VERSION "2021.24.4"

NS_ :

BS_:

BU_: VEH CH Receiver X

BA_DEF_ BO_ "GenMsgSendType" ENUM "Cyclic";
BA_DEF_ BO_ "GenMsgCycleTime" INT 0 10000;

BO_ 1274 USM_alertCleared: 8 Vector__XXX
 SG_ USM_alertClearedID : 0|8@1+ (1,0) [0|0] "" Vector__XXX

BO_ 1278 USM_logging10Hz: 8 Vector__XXX
 SG_ USM_rearSensorsHSDCurrent : 10|10@1+ (0.005865102639296188,0) [0|0] "" Vector__XXX
 SG_ USM_frontSensorsHSDCurrent : 0|10@1+ (0.005865102639296188,0) [0|0] "" Vector__XXX

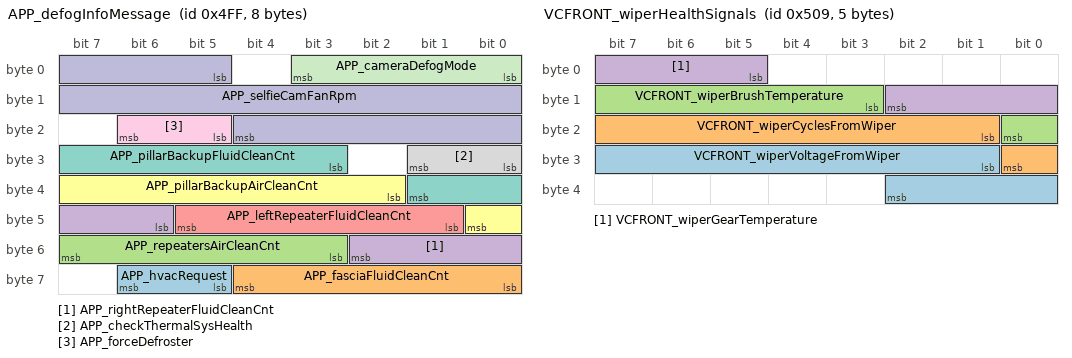
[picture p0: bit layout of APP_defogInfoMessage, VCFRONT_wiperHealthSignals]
BO_ 1279 APP_defogInfoMessage: 8 Vector__XXX
 SG_ APP_hvacRequest : 61|2@1+ (1,0) [0|0] "" Vector__XXX
 SG_ APP_fasciaFluidCleanCnt : 56|5@1+ (1,0) [0|0] "" Vector__XXX
 SG_ APP_repeatersAirCleanCnt : 51|5@1+ (1,0) [0|0] "" Vector__XXX
 SG_ APP_rightRepeaterFluidCleanCnt : 46|5@1+ (1,0) [0|0] "" Vector__XXX
 SG_ APP_leftRepeaterFluidCleanCnt : 41|5@1+ (1,0) [0|0] "" Vector__XXX
 SG_ APP_pillarBackupAirCleanCnt : 34|7@1+ (1,0) [0|0] "" Vector__XXX
 SG_ APP_pillarBackupFluidCleanCnt : 27|7@1+ (1,0) [0|0] "" Vector__XXX
 SG_ APP_checkThermalSysHealth : 24|2@1+ (1,0) [0|0] "" Vector__XXX
 SG_ APP_forceDefroster : 21|2@1+ (1,0) [0|0] "" Vector__XXX
 SG_ APP_selfieCamFanRpm : 5|16@1+ (1,0) [0|0] "" Vector__XXX
 SG_ APP_cameraDefogMode : 0|4@1+ (1,0) [0|0] "" Vector__XXX

BO_ 1281 VCFRONT_bootID: 12 Vector__XXX
 SG_ VCFRONT_bootFirmwareType : 63|8@0+ (1,0) [0|0] "" Vector__XXX
 SG_ VCFRONT_bootUsageId : 39|16@0+ (1,0) [0|0] "" Vector__XXX
 SG_ VCFRONT_bootAssemblyId : 31|8@0+ (1,0) [0|0] "" Vector__XXX
 SG_ VCFRONT_bootPcbaId : 23|8@0+ (1,0) [0|0] "" Vector__XXX
 SG_ VCFRONT_bootComponentId : 7|16@0+ (1,0) [0|0] "" Vector__XXX

BO_ 1283 VCRIGHT_bootID: 12 Vector__XXX
 SG_ VCRIGHT_bootFirmwareType : 63|8@0+ (1,0) [0|0] "" Vector__XXX
 SG_ VCRIGHT_bootUsageId : 39|16@0+ (1,0) [0|0] "" Vector__XXX
 SG_ VCRIGHT_bootAssemblyId : 31|8@0+ (1,0) [0|0] "" Vector__XXX
 SG_ VCRIGHT_bootPcbaId : 23|8@0+ (1,0) [0|0] "" Vector__XXX
 SG_ VCRIGHT_bootComponentId : 7|16@0+ (1,0) [0|0] "" Vector__XXX

BO_ 1284 PCS_bootID: 12 Vector__XXX
 SG_ PCS_bootFirmwareType : 63|8@0+ (1,0) [0|0] "" Vector__XXX
 SG_ PCS_bootUsageId : 39|16@0+ (1,0) [0|0] "" Vector__XXX
 SG_ PCS_bootAssemblyId : 31|8@0+ (1,0) [0|0] "" Vector__XXX
 SG_ PCS_bootPcbaId : 23|8@0+ (1,0) [0|0] "" Vector__XXX
 SG_ PCS_bootComponentId : 7|16@0+ (1,0) [0|0] "" Vector__XXX

BO_ 1285 ESP_alertLog: 8 Vector__XXX
 SG_ ESP_alertState : 15|1@1+ (1,0) [0|0] "" Vector__XXX
 SG_ ESP_alertID : 0|9@1+ (1,0) [0|0] "" Vector__XXX

BO_ 1289 VCFRONT_wiperHealthSignals: 5 Vector__XXX
 SG_ VCFRONT_wiperVoltageFromWiper : 25|10@1+ (0.01,8) [0|0] "" Vector__XXX
 SG_ VCFRONT_wiperCyclesFromWiper : 17|8@1+ (6000,0) [0|0] "" Vector__XXX
 SG_ VCFRONT_wiperBrushTemperature : 11|6@1+ (1.6,100) [0|0] "" Vector__XXX
 SG_ VCFRONT_wiperGearTemperature : 5|6@1+ (1,40) [0|0] "" Vector__XXX

BO_ 1290 HVP_alertLog: 8 Vector__XXX
 SG_ HVP_a040_negCtrAuxOpen m40 : 63|1@1+ (1,0) [0|0] "" Vector__XXX
 SG_ HVP_a040_posCtrAuxOpen m40 : 62|1@1+ (1,0) [0|0] "" Vector__XXX
 SG_ HVP_a026_difVoltage m26 : 56|8@1+ (0.04,0) [0|0] "" Vector__XXX
 SG_ HVP_a033_pwmDutyCyleNegative m33 : 56|8@1+ (1,0) [0|0] "" Vector__XXX
 SG_ HVP_a035_pwmDutyCyleNegative m35 : 56|8@1+ (1,0) [0|0] "" Vector__XXX
 SG_ HVP_a063_numFailedBricks m63 : 56|8@1+ (1,0) [0|0] "" Vector__XXX
 SG_ HVP_a064_numFailedAux m64 : 56|8@1+ (1,0) [0|0] "" Vector__XXX
 SG_ HVP_a018_gpioChgEnable m18 : 52|1@1+ (1,0) [0|0] "" Vector__XXX
 SG_ HVP_a018_gpioDcDcEnable m18 : 51|1@1+ (1,0) [0|0] "" Vector__XXX
 SG_ HVP_a049_negCtrState m49 : 51|3@1+ (1,0) [0|0] "" Vector__XXX
 SG_ HVP_a050_negCtrState m50 : 51|3@1+ (1,0) [0|0] "" Vector__XXX
 SG_ HVP_a056_negFcContactorState m56 : 51|3@1+ (1,0) [0|0] "" Vector__XXX
 SG_ HVP_a018_gpioLogicPowerEnable m18 : 50|1@1+ (1,0) [0|0] "" Vector__XXX
 SG_ HVP_a018_pcsHardwareOkToBePowerC m18 : 49|1@1+ (1,0) [0|0] "" Vector__XXX
 SG_ HVP_a000_alertDataW2 m0 : 48|16@1+ (1,0) [0|0] "" Vector__XXX
 SG_ HVP_a018_hvcHardwareSupportsCycl m18 : 48|1@1+ (1,0) [0|0] "" Vector__XXX
 SG_ HVP_a020_shuntTemperature m20 : 48|16@1- (0.01,0) [0|0] "" Vector__XXX
 SG_ HVP_a025_packVoltage m25 : 48|16@1+ (0.1,0) [0|0] "" Vector__XXX
 SG_ HVP_a026_dirVoltage m26 : 48|8@1+ (0.04,0) [0|0] "" Vector__XXX
 SG_ HVP_a033_pwmDutyCylePositive m33 : 48|8@1+ (1,0) [0|0] "" Vector__XXX
 SG_ HVP_a035_pwmDutyCylePositive m35 : 48|8@1+ (1,0) [0|0] "" Vector__XXX
 SG_ HVP_a046_asicTemperature m46 : 48|16@1- (0.01,0) [0|0] "" Vector__XXX
 SG_ HVP_a049_posCtrState m49 : 48|3@1+ (1,0) [0|0] "" Vector__XXX
 SG_ HVP_a050_posCtrState m50 : 48|3@1+ (1,0) [0|0] "" Vector__XXX
 SG_ HVP_a051_energyReserveV m51 : 48|16@1+ (0.001,0) [0|0] "" Vector__XXX
 SG_ HVP_a056_posFcContactorState m56 : 48|3@1+ (1,0) [0|0] "" Vector__XXX
 SG_ HVP_a060_stackId m60 : 48|8@1+ (1,1) [0|0] "" Vector__XXX
 SG_ HVP_a063_brickId m63 : 48|8@1+ (1,1) [0|0] "" Vector__XXX
 SG_ HVP_a064_auxId m64 : 48|8@1+ (1,1) [0|0] "" Vector__XXX
 SG_ HVP_a068_energyReserveV m68 : 48|16@1+ (0.001,0) [0|0] "" Vector__XXX
 SG_ HVP_a040_negCtrVoltageDrop m40 : 47|15@1- (0.1,0) [0|0] "" Vector__XXX
 SG_ HVP_a018_remainingPcsRecoveriesA m18 : 46|2@1+ (1,0) [0|0] "" Vector__XXX
 SG_ HVP_a018_remainingPcsPowerCycles m18 : 44|2@1+ (1,0) [0|0] "" Vector__XXX
 SG_ HVP_a021_Aout m21 : 44|14@1+ (0.001,0) [0|0] "" Vector__XXX
 SG_ HVP_a021_LowSide m21 : 43|1@1+ (1,0) [0|0] "" Vector__XXX
 SG_ HVP_a056_negPackContactorState m56 : 43|3@1+ (1,0) [0|0] "" Vector__XXX
 SG_ HVP_a021_HighSide m21 : 42|1@1+ (1,0) [0|0] "" Vector__XXX
 SG_ HVP_a021_OneShotSequence m21 : 41|1@1+ (1,0) [0|0] "" Vector__XXX
 SG_ HVP_a022_SquibResistance m22 : 40|16@1+ (0.001,0) [0|0] "" Vector__XXX
 SG_ HVP_a026_internalVoltage m26 : 40|8@1+ (0.04,0) [0|0] "" Vector__XXX
 SG_ HVP_a036_pyroFiringAttempt m36 : 40|4@1+ (1,0) [0|0] "" Vector__XXX
 SG_ HVP_a056_posPackContactorState m56 : 40|3@1+ (1,0) [0|0] "" Vector__XXX
 SG_ HVP_a009_primaryChainSensor m9 : 39|1@1+ (1,0) [0|0] "" Vector__XXX
 SG_ HVP_a010_primaryChainSensor m10 : 39|1@1+ (1,0) [0|0] "" Vector__XXX
 SG_ HVP_a008_primaryChainSensor m8 : 38|1@1+ (1,0) [0|0] "" Vector__XXX
 SG_ HVP_a058_VrefType m58 : 38|2@1+ (1,0) [0|0] "" Vector__XXX
 SG_ HVP_a059_VrefType m59 : 38|2@1+ (1,0) [0|0] "" Vector__XXX
 SG_ HVP_a042_cpVersionMismatch m42 : 37|1@1+ (1,0) [0|0] "" Vector__XXX
 SG_ HVP_a041_dcLinkOverVoltage m41 : 36|1@1+ (1,0) [0|0] "" Vector__XXX
 SG_ HVP_a042_resetRequestRequired m42 : 36|1@1+ (1,0) [0|0] "" Vector__XXX
 SG_ HVP_a057_readSTAT m57 : 36|1@1+ (1,0) [0|0] "" Vector__XXX
 SG_ HVP_a058_VrefStatus m58 : 36|2@1+ (1,0) [0|0] "" Vector__XXX
 SG_ HVP_a059_VrefStatus m59 : 36|2@1+ (1,0) [0|0] "" Vector__XXX
 SG_ HVP_a041_pyroFault m41 : 35|1@1+ (1,0) [0|0] "" Vector__XXX
 SG_ HVP_a042_packContactorOpening m42 : 35|1@1+ (1,0) [0|0] "" Vector__XXX
 SG_ HVP_a057_readAUXB m57 : 35|1@1+ (1,0) [0|0] "" Vector__XXX
 SG_ HVP_a041_resetRequestRequired m41 : 34|1@1+ (1,0) [0|0] "" Vector__XXX
 SG_ HVP_a042_packContactorClosing m42 : 34|1@1+ (1,0) [0|0] "" Vector__XXX
 SG_ HVP_a057_readAUXA m57 : 34|1@1+ (1,0) [0|0] "" Vector__XXX
 SG_ HVP_a041_fcContactorOpening m41 : 33|1@1+ (1,0) [0|0] "" Vector__XXX
 SG_ HVP_a042_shuntCurrentMia m42 : 33|1@1+ (1,0) [0|0] "" Vector__XXX
 SG_ HVP_a057_readSNF m57 : 33|1@1+ (1,0) [0|0] "" Vector__XXX
 SG_ HVP_a000_alertDataW1 m0 : 32|16@1+ (1,0) [0|0] "" Vector__XXX
 SG_ HVP_a008_sensorId m8 : 32|6@1+ (1,1) [0|0] "" Vector__XXX
 SG_ HVP_a009_brickId m9 : 32|7@1+ (1,1) [0|0] "" Vector__XXX
 SG_ HVP_a010_brickId m10 : 32|7@1+ (1,1) [0|0] "" Vector__XXX
 SG_ HVP_a013_bmbChainBreakType m13 : 32|3@1+ (1,0) [0|0] "" Vector__XXX
 SG_ HVP_a018_battery12V m18 : 32|12@1+ (0.1,0) [0|0] "" Vector__XXX
 SG_ HVP_a020_shuntCurrentAux m20 : 32|16@1- (0.1,0) [0|0] "" Vector__XXX
 SG_ HVP_a023_reason m23 : 32|2@1+ (1,0) [0|0] "" Vector__XXX
 SG_ HVP_a025_voltage2 m25 : 32|16@1+ (0.1,0) [0|0] "" Vector__XXX
 SG_ HVP_a026_outputVoltage m26 : 32|8@1+ (0.04,0) [0|0] "" Vector__XXX
 SG_ HVP_a028_sumOfBrickV m28 : 32|16@1+ (0.1,0) [0|0] "" Vector__XXX
 SG_ HVP_a030_dcPositiveLinkV m30 : 32|16@1- (0.1,0) [0|0] "" Vector__XXX
 SG_ HVP_a031_dcNegativeLinkV m31 : 32|16@1- (0.1,0) [0|0] "" Vector__XXX
 SG_ HVP_a033_coilCurrent m33 : 32|16@1+ (0.1,0) [0|0] "" Vector__XXX
 SG_ HVP_a035_coilCurrent m35 : 32|16@1+ (0.1,0) [0|0] "" Vector__XXX
 SG_ HVP_a040_posCtrVoltageDrop m40 : 32|15@1- (0.1,0) [0|0] "" Vector__XXX
 SG_ HVP_a041_fcContactorClosing m41 : 32|1@1+ (1,0) [0|0] "" Vector__XXX
 SG_ HVP_a042_shuntHwMia m42 : 32|1@1+ (1,0) [0|0] "" Vector__XXX
 SG_ HVP_a046_shuntTemperature m46 : 32|16@1- (0.01,0) [0|0] "" Vector__XXX
 SG_ HVP_a047_auxCurrent m47 : 32|16@1- (0.1,0) [0|0] "" Vector__XXX
 SG_ HVP_a049_coilCurrent m49 : 32|16@1+ (0.1,0) [0|0] "" Vector__XXX
 SG_ HVP_a050_coilCurrent m50 : 32|16@1+ (0.1,0) [0|0] "" Vector__XXX
 SG_ HVP_a051_shuntCurrent m51 : 32|16@1- (0.1,0) [0|0] "" Vector__XXX
 SG_ HVP_a052_regErrorType m52 : 32|8@1+ (1,0) [0|0] "" Vector__XXX
 SG_ HVP_a053_dcLinkVoltage m53 : 32|16@1+ (0.01,0) [0|0] "" Vector__XXX
 SG_ HVP_a057_readSNE m57 : 32|1@1+ (1,0) [0|0] "" Vector__XXX
 SG_ HVP_a058_bmbDeviceId m58 : 32|4@1+ (1,1) [0|0] "" Vector__XXX
 SG_ HVP_a059_bmbDeviceId m59 : 32|4@1+ (1,1) [0|0] "" Vector__XXX
 SG_ HVP_a060_sumBrickVoltage m60 : 32|16@1+ (0.00128,0) [0|0] "" Vector__XXX
 SG_ HVP_a061_auxCurrent m61 : 32|16@1- (0.1,0) [0|0] "" Vector__XXX
 SG_ HVP_a063_secondaryBrickVoltage m63 : 32|16@1+ (0.0001,0) [0|0] "" Vector__XXX
 SG_ HVP_a064_secondaryAuxVoltage m64 : 32|16@1+ (0.0001,0) [0|0] "" Vector__XXX
 SG_ HVP_a068_shuntCurrent m68 : 32|16@1- (0.1,0) [0|0] "" Vector__XXX
 SG_ HVP_a041_gpoRequestActive m41 : 31|1@1+ (1,0) [0|0] "" Vector__XXX
 SG_ HVP_a042_contactorStateWelded m42 : 31|1@1+ (1,0) [0|0] "" Vector__XXX
 SG_ HVP_a044_cpVersionMismatch m44 : 31|1@1+ (1,0) [0|0] "" Vector__XXX
 SG_ HVP_a057_readSND m57 : 31|1@1+ (1,0) [0|0] "" Vector__XXX
 SG_ HVP_a041_packVoltageMismatch m41 : 30|1@1+ (1,0) [0|0] "" Vector__XXX
 SG_ HVP_a042_hvilFault m42 : 30|1@1+ (1,0) [0|0] "" Vector__XXX
 SG_ HVP_a044_contactorOpened m44 : 30|1@1+ (1,0) [0|0] "" Vector__XXX
 SG_ HVP_a057_readSNC m57 : 30|1@1+ (1,0) [0|0] "" Vector__XXX
 SG_ HVP_a012_bmbCommStatusTypeB m12 : 29|2@1+ (1,0) [0|0] "" Vector__XXX
 SG_ HVP_a013_bmbCommStatusTypeB m13 : 29|2@1+ (1,0) [0|0] "" Vector__XXX
 SG_ HVP_a041_shuntCurrentMia m41 : 29|1@1+ (1,0) [0|0] "" Vector__XXX
 SG_ HVP_a042_packVoltageMismatch m42 : 29|1@1+ (1,0) [0|0] "" Vector__XXX
 SG_ HVP_a044_packVoltageMismatch m44 : 29|1@1+ (1,0) [0|0] "" Vector__XXX
 SG_ HVP_a057_readSNB m57 : 29|1@1+ (1,0) [0|0] "" Vector__XXX
 SG_ HVP_a041_shuntHwMia m41 : 28|1@1+ (1,0) [0|0] "" Vector__XXX
 SG_ HVP_a042_supplyVer m42 : 28|1@1+ (1,0) [0|0] "" Vector__XXX
 SG_ HVP_a044_supplyVer m44 : 28|1@1+ (1,0) [0|0] "" Vector__XXX
 SG_ HVP_a057_readSNA m57 : 28|1@1+ (1,0) [0|0] "" Vector__XXX
 SG_ HVP_a041_contactorStateWelded m41 : 27|1@1+ (1,0) [0|0] "" Vector__XXX
 SG_ HVP_a042_supply12V m42 : 27|1@1+ (1,0) [0|0] "" Vector__XXX
 SG_ HVP_a044_supply12V m44 : 27|1@1+ (1,0) [0|0] "" Vector__XXX
 SG_ HVP_a057_readCVF m57 : 27|1@1+ (1,0) [0|0] "" Vector__XXX
 SG_ HVP_a041_hvilFault m41 : 26|1@1+ (1,0) [0|0] "" Vector__XXX
 SG_ HVP_a042_cpFault m42 : 26|1@1+ (1,0) [0|0] "" Vector__XXX
 SG_ HVP_a043_contactorOpened m43 : 26|1@1+ (1,0) [0|0] "" Vector__XXX
 SG_ HVP_a044_cpFault m44 : 26|1@1+ (1,0) [0|0] "" Vector__XXX
 SG_ HVP_a057_readCVE m57 : 26|1@1+ (1,0) [0|0] "" Vector__XXX
 SG_ HVP_a021_SquibResistance m21 : 25|16@1+ (0.001,0) [0|0] "" Vector__XXX
 SG_ HVP_a041_bmbMia m41 : 25|1@1+ (1,0) [0|0] "" Vector__XXX
 SG_ HVP_a042_cpMia m42 : 25|1@1+ (1,0) [0|0] "" Vector__XXX
 SG_ HVP_a043_bmbMia m43 : 25|1@1+ (1,0) [0|0] "" Vector__XXX
 SG_ HVP_a044_cpMia m44 : 25|1@1+ (1,0) [0|0] "" Vector__XXX
 SG_ HVP_a057_readCVD m57 : 25|1@1+ (1,0) [0|0] "" Vector__XXX
 SG_ HVP_a012_breakLocationB m12 : 24|5@1+ (1,0) [0|0] "" Vector__XXX
 SG_ HVP_a013_breakLocationB m13 : 24|5@1+ (1,0) [0|0] "" Vector__XXX
 SG_ HVP_a021_VstTestFailed m21 : 24|1@1+ (1,0) [0|0] "" Vector__XXX
 SG_ HVP_a022_Aout m22 : 24|14@1+ (0.001,0) [0|0] "" Vector__XXX
 SG_ HVP_a026_inputVoltage m26 : 24|8@1+ (0.04,0) [0|0] "" Vector__XXX
 SG_ HVP_a036_pyroFiringTime m36 : 24|16@1+ (1,0) [0|0] "" Vector__XXX
 SG_ HVP_a040_coilCurrent m40 : 24|8@1+ (0.1,0) [0|0] "" Vector__XXX
 SG_ HVP_a041_notAllowedtoEnergize m41 : 24|1@1+ (1,0) [0|0] "" Vector__XXX
 SG_ HVP_a042_bmsHvsMia m42 : 24|1@1+ (1,0) [0|0] "" Vector__XXX
 SG_ HVP_a043_notAllowedtoEnergize m43 : 24|1@1+ (1,0) [0|0] "" Vector__XXX
 SG_ HVP_a044_bmsHvsMia m44 : 24|1@1+ (1,0) [0|0] "" Vector__XXX
 SG_ HVP_a056_shuntCurrent m56 : 24|16@1- (0.1,0) [0|0] "" Vector__XXX
 SG_ HVP_a057_readCVC m57 : 24|1@1+ (1,0) [0|0] "" Vector__XXX
 SG_ HVP_a021_SquibResTestFailed m21 : 23|1@1+ (1,0) [0|0] "" Vector__XXX
 SG_ HVP_a041_packContactorHw m41 : 23|1@1+ (1,0) [0|0] "" Vector__XXX
 SG_ HVP_a042_notAllowedtoEnergize m42 : 23|1@1+ (1,0) [0|0] "" Vector__XXX
 SG_ HVP_a043_packContactorHw m43 : 23|1@1+ (1,0) [0|0] "" Vector__XXX
 SG_ HVP_a044_notAllowedtoEnergize m44 : 23|1@1+ (1,0) [0|0] "" Vector__XXX
 SG_ HVP_a057_readCVB m57 : 23|1@1+ (1,0) [0|0] "" Vector__XXX
 SG_ HVP_a021_PyroLeakTestFailed m21 : 22|1@1+ (1,0) [0|0] "" Vector__XXX
 SG_ HVP_a041_crashEvent m41 : 22|1@1+ (1,0) [0|0] "" Vector__XXX
 SG_ HVP_a042_fcContactorHw m42 : 22|1@1+ (1,0) [0|0] "" Vector__XXX
 SG_ HVP_a043_crashEvent m43 : 22|1@1+ (1,0) [0|0] "" Vector__XXX
 SG_ HVP_a044_fcContactorHw m44 : 22|1@1+ (1,0) [0|0] "" Vector__XXX
 SG_ HVP_a057_readCVA m57 : 22|1@1+ (1,0) [0|0] "" Vector__XXX
 SG_ HVP_a012_bmbCommStatusTypeA m12 : 21|2@1+ (1,0) [0|0] "" Vector__XXX
 SG_ HVP_a013_bmbCommStatusTypeA m13 : 21|2@1+ (1,0) [0|0] "" Vector__XXX
 SG_ HVP_a021_RefCurrentTestFailed m21 : 21|1@1+ (1,0) [0|0] "" Vector__XXX
 SG_ HVP_a022_LowSide m22 : 21|1@1+ (1,0) [0|0] "" Vector__XXX
 SG_ HVP_a041_underVoltage m41 : 21|1@1+ (1,0) [0|0] "" Vector__XXX
 SG_ HVP_a042_crashEvent m42 : 21|1@1+ (1,0) [0|0] "" Vector__XXX
 SG_ HVP_a043_underVoltage m43 : 21|1@1+ (1,0) [0|0] "" Vector__XXX
 SG_ HVP_a044_crashEvent m44 : 21|1@1+ (1,0) [0|0] "" Vector__XXX
 SG_ HVP_a065_brickId m65 : 21|7@1+ (1,1) [0|0] "" Vector__XXX
 SG_ HVP_a021_LowSideSwitchTestFailed m21 : 20|1@1+ (1,0) [0|0] "" Vector__XXX
 SG_ HVP_a022_HighSide m22 : 20|1@1+ (1,0) [0|0] "" Vector__XXX
 SG_ HVP_a041_overTemperature m41 : 20|1@1+ (1,0) [0|0] "" Vector__XXX
 SG_ HVP_a042_overTemperature m42 : 20|1@1+ (1,0) [0|0] "" Vector__XXX
 SG_ HVP_a043_overTemperature m43 : 20|1@1+ (1,0) [0|0] "" Vector__XXX
 SG_ HVP_a044_overTemperature m44 : 20|1@1+ (1,0) [0|0] "" Vector__XXX
 SG_ HVP_a067_hvilTypeIsFromCal m67 : 20|1@1+ (1,0) [0|0] "" Vector__XXX
 SG_ HVP_a021_HighSideSwitchTestFaile m21 : 19|1@1+ (1,0) [0|0] "" Vector__XXX
 SG_ HVP_a022_OneShotSequence m22 : 19|1@1+ (1,0) [0|0] "" Vector__XXX
 SG_ HVP_a041_overVoltage m41 : 19|1@1+ (1,0) [0|0] "" Vector__XXX
 SG_ HVP_a042_overVoltage m42 : 19|1@1+ (1,0) [0|0] "" Vector__XXX
 SG_ HVP_a043_overVoltage m43 : 19|1@1+ (1,0) [0|0] "" Vector__XXX
 SG_ HVP_a044_overVoltage m44 : 19|1@1+ (1,0) [0|0] "" Vector__XXX
 SG_ HVP_a021_ErTestFailed m21 : 18|1@1+ (1,0) [0|0] "" Vector__XXX
 SG_ HVP_a022_PyroLeakTestFailed m22 : 18|1@1+ (1,0) [0|0] "" Vector__XXX
 SG_ HVP_a041_overDischargeCurrent m41 : 18|1@1+ (1,0) [0|0] "" Vector__XXX
 SG_ HVP_a042_overDischargeCurrent m42 : 18|1@1+ (1,0) [0|0] "" Vector__XXX
 SG_ HVP_a043_overDischargeCurrent m43 : 18|1@1+ (1,0) [0|0] "" Vector__XXX
 SG_ HVP_a044_overDischargeCurrent m44 : 18|1@1+ (1,0) [0|0] "" Vector__XXX
 SG_ HVP_a057_bmbDeviceId m57 : 18|4@1+ (1,1) [0|0] "" Vector__XXX
 SG_ HVP_a067_hvilTypeFromGateway m67 : 18|2@1+ (1,0) [0|0] "" Vector__XXX
 SG_ HVP_a039_negContactorFailed m39 : 17|1@1+ (1,0) [0|0] "" Vector__XXX
 SG_ HVP_a041_overChargeCurrent m41 : 17|1@1+ (1,0) [0|0] "" Vector__XXX
 SG_ HVP_a042_overChargeCurrent m42 : 17|1@1+ (1,0) [0|0] "" Vector__XXX
 SG_ HVP_a043_overChargeCurrent m43 : 17|1@1+ (1,0) [0|0] "" Vector__XXX
 SG_ HVP_a044_overChargeCurrent m44 : 17|1@1+ (1,0) [0|0] "" Vector__XXX
 SG_ HVP_a000_alertDataW0 m0 : 16|16@1+ (1,0) [0|0] "" Vector__XXX
 SG_ HVP_a003_programCounter m3 : 16|32@1+ (1,0) [0|0] "" Vector__XXX
 SG_ HVP_a005_current m5 : 16|24@1- (0.001,0) [0|0] "" Vector__XXX
 SG_ HVP_a006_current m6 : 16|24@1- (0.001,0) [0|0] "" Vector__XXX
 SG_ HVP_a007_current m7 : 16|24@1- (0.001,0) [0|0] "" Vector__XXX
 SG_ HVP_a008_temperature m8 : 16|16@1- (0.01,0) [0|0] "" Vector__XXX
 SG_ HVP_a009_brickVoltage m9 : 16|16@1- (0.001,0) [0|0] "" Vector__XXX
 SG_ HVP_a010_brickVoltage m10 : 16|16@1- (0.001,0) [0|0] "" Vector__XXX
 SG_ HVP_a012_breakLocationA m12 : 16|5@1+ (1,0) [0|0] "" Vector__XXX
 SG_ HVP_a013_breakLocationA m13 : 16|5@1+ (1,0) [0|0] "" Vector__XXX
 SG_ HVP_a018_dcLinkVoltage m18 : 16|16@1+ (0.01,0) [0|0] "" Vector__XXX
 SG_ HVP_a020_energyReserveV m20 : 16|16@1+ (0.001,0) [0|0] "" Vector__XXX
 SG_ HVP_a021_pyroStatus m21 : 16|2@1+ (1,0) [0|0] "" Vector__XXX
 SG_ HVP_a022_pyroStatus m22 : 16|2@1+ (1,0) [0|0] "" Vector__XXX
 SG_ HVP_a023_bmbDeviceMask m23 : 16|16@1+ (1,0) [0|0] "" Vector__XXX
 SG_ HVP_a024_voltage m24 : 16|16@1+ (0.1,0) [0|0] "" Vector__XXX
 SG_ HVP_a025_voltage1 m25 : 16|16@1+ (0.1,0) [0|0] "" Vector__XXX
 SG_ HVP_a026_hvilStatus m26 : 16|4@1+ (1,0) [0|0] "" Vector__XXX
 SG_ HVP_a028_packVoltage m28 : 16|16@1+ (0.1,0) [0|0] "" Vector__XXX
 SG_ HVP_a030_packPositiveLinkV m30 : 16|16@1- (0.1,0) [0|0] "" Vector__XXX
 SG_ HVP_a031_packNegativeLinkV m31 : 16|16@1- (0.1,0) [0|0] "" Vector__XXX
 SG_ HVP_a033_contactorPowerV m33 : 16|16@1+ (0.1,0) [0|0] "" Vector__XXX
 SG_ HVP_a035_contactorPowerV m35 : 16|16@1+ (0.1,0) [0|0] "" Vector__XXX
 SG_ HVP_a036_pyroFiringHandle m36 : 16|4@1+ (1,0) [0|0] "" Vector__XXX
 SG_ HVP_a037_pyroFiringHandle m37 : 16|4@1+ (1,0) [0|0] "" Vector__XXX
 SG_ HVP_a039_posContactorFailed m39 : 16|1@1+ (1,0) [0|0] "" Vector__XXX
 SG_ HVP_a040_powerVoltage m40 : 16|8@1+ (0.1,0) [0|0] "" Vector__XXX
 SG_ HVP_a041_overCurrent m41 : 16|1@1+ (1,0) [0|0] "" Vector__XXX
 SG_ HVP_a042_overCurrent m42 : 16|1@1+ (1,0) [0|0] "" Vector__XXX
 SG_ HVP_a043_overCurrent m43 : 16|1@1+ (1,0) [0|0] "" Vector__XXX
 SG_ HVP_a044_overCurrent m44 : 16|1@1+ (1,0) [0|0] "" Vector__XXX
 SG_ HVP_a045_dcLinkVoltage m45 : 16|16@1+ (0.1,0) [0|0] "" Vector__XXX
 SG_ HVP_a046_shuntCurrent m46 : 16|16@1- (0.1,0) [0|0] "" Vector__XXX
 SG_ HVP_a047_shuntCurrent m47 : 16|16@1- (0.1,0) [0|0] "" Vector__XXX
 SG_ HVP_a049_contactorPowerV m49 : 16|16@1+ (0.1,0) [0|0] "" Vector__XXX
 SG_ HVP_a050_contactorPowerV m50 : 16|16@1+ (0.1,0) [0|0] "" Vector__XXX
 SG_ HVP_a051_shuntTemperature m51 : 16|16@1- (0.01,0) [0|0] "" Vector__XXX
 SG_ HVP_a052_bmbDeviceMask m52 : 16|16@1+ (1,0) [0|0] "" Vector__XXX
 SG_ HVP_a053_packVoltage m53 : 16|16@1+ (0.01,0) [0|0] "" Vector__XXX
 SG_ HVP_a056_diagnosis m56 : 16|2@1+ (1,0) [0|0] "" Vector__XXX
 SG_ HVP_a057_bmbDiagnosticsType m57 : 16|2@1+ (1,0) [0|0] "" Vector__XXX
 SG_ HVP_a058_VrefSample m58 : 16|16@1+ (0.0001,0) [0|0] "" Vector__XXX
 SG_ HVP_a059_VrefSample m59 : 16|16@1+ (0.0001,0) [0|0] "" Vector__XXX
 SG_ HVP_a060_stackVoltage m60 : 16|16@1+ (0.00128,0) [0|0] "" Vector__XXX
 SG_ HVP_a061_shuntCurrent m61 : 16|16@1- (0.1,0) [0|0] "" Vector__XXX
 SG_ HVP_a062_bmbDeviceMask m62 : 16|16@1+ (1,0) [0|0] "" Vector__XXX
 SG_ HVP_a063_primaryBrickVoltage m63 : 16|16@1+ (0.0001,0) [0|0] "" Vector__XXX
 SG_ HVP_a064_primaryAuxVoltage m64 : 16|16@1+ (0.0001,0) [0|0] "" Vector__XXX
 SG_ HVP_a067_hvilTypeFromHvp m67 : 16|2@1+ (1,0) [0|0] "" Vector__XXX
 SG_ HVP_a068_shuntTemperature m68 : 16|16@1- (0.01,0) [0|0] "" Vector__XXX
 SG_ HVP_a069_numFramesDropped m69 : 16|16@1+ (1,0) [0|0] "" Vector__XXX
 SG_ HVP_a070_numFramesDropped m70 : 16|16@1+ (1,0) [0|0] "" Vector__XXX
 SG_ HVP_a071_passivePyroReferenceVol m71 : 16|16@1- (0.001,0) [0|0] "" Vector__XXX
 SG_ HVP_alertSet : 15|1@1+ (1,0) [0|0] "" Vector__XXX
 SG_ HVP_alertID M : 0|7@1+ (1,0) [0|0] "" Vector__XXX

BO_ 1294 CP_alertLog: 8 Vector__XXX
 SG_ CP_a005_latchEngaged m5 : 63|1@1+ (1,0) [0|0] "" Vector__XXX
 SG_ CP_a065_inletVanityLedFailed m65 : 63|1@1+ (1,0) [0|0] "" Vector__XXX
 SG_ CP_a118_cableConnected m118 : 63|1@1+ (1,0) [0|0] "" Vector__XXX
 SG_ CP_a005_superchargerConnected m5 : 62|1@1+ (1,0) [0|0] "" Vector__XXX
 SG_ CP_a050_consecutiveAlertCount m50 : 62|2@1+ (1,0) [0|0] "" Vector__XXX
 SG_ CP_a065_inletHarnessIdFailed m65 : 62|1@1+ (1,0) [0|0] "" Vector__XXX
 SG_ CP_a076_inductiveErrorUnderRange m76 : 62|1@1+ (1,0) [0|0] "" Vector__XXX
 SG_ CP_a065_hvCoverFailed m65 : 61|1@1+ (1,0) [0|0] "" Vector__XXX
 SG_ CP_a076_inductiveErrorOverRange m76 : 61|1@1+ (1,0) [0|0] "" Vector__XXX
 SG_ CP_a076_inductiveErrorWatchdog m76 : 60|1@1+ (1,0) [0|0] "" Vector__XXX
 SG_ CP_a120_cableType m120 : 60|3@1+ (1,0) [0|0] "" Vector__XXX
 SG_ CP_a076_inductiveErrorAmplitude m76 : 59|1@1+ (1,0) [0|0] "" Vector__XXX
 SG_ CP_a095_fcBrand m95 : 59|1@1+ (1,0) [0|0] "" Vector__XXX
 SG_ CP_a065_pilotState m65 : 58|3@1+ (1,0) [0|0] "" Vector__XXX
 SG_ CP_a068_doorPresent m68 : 58|1@1+ (1,0) [0|0] "" Vector__XXX
 SG_ CP_a126_cableConnected m126 : 58|1@1+ (1,0) [0|0] "" Vector__XXX
 SG_ CP_a118_tcpIpTaskMiaTime m118 : 57|6@1+ (100,0) [0|0] "" Vector__XXX
 SG_ CP_a008_stackUsed m8 : 56|7@1+ (1,0) [0|0] "" Vector__XXX
 SG_ CP_a076_inductiveDoorState m76 : 56|3@1+ (1,0) [0|0] "" Vector__XXX
 SG_ CP_a095_fcType m95 : 56|3@1+ (1,0) [0|0] "" Vector__XXX
 SG_ CP_a097_WKUP_WISR_CAN m97 : 55|1@1+ (1,0) [0|0] "" Vector__XXX
 SG_ CP_a031_hallSensorFiltered m31 : 54|10@1+ (0.004887487782,0) [0|0] "" Vector__XXX
 SG_ CP_a032_hallSensorFiltered m32 : 54|10@1+ (0.004887487782,0) [0|0] "" Vector__XXX
 SG_ CP_a097_WKUP_WISR_RTC m97 : 54|1@1+ (1,0) [0|0] "" Vector__XXX
 SG_ CP_a097_ME_IMTS_SEA m97 : 53|1@1+ (1,0) [0|0] "" Vector__XXX
 SG_ CP_a152_minPilotSwcanLow m152 : 53|9@1+ (0.02837573385518591,0) [0|0] "" Vector__XXX
 SG_ CP_a159_minPilotSwcanLow m159 : 53|9@1+ (0.02837573385518591,0) [0|0] "" Vector__XXX
 SG_ CP_a162_minPilotSwcanLow m162 : 53|9@1+ (0.02837573385518591,0) [0|0] "" Vector__XXX
 SG_ CP_a005_evseCurrent m5 : 52|10@1+ (0.39100684261974583,0) [0|0] "" Vector__XXX
 SG_ CP_a008_StackAlert m8 : 52|1@1+ (1,0) [0|0] "" Vector__XXX
 SG_ CP_a097_ME_IMTS_NMA m97 : 52|1@1+ (1,0) [0|0] "" Vector__XXX
 SG_ CP_a120_dcPinTemp m120 : 52|8@1+ (0.8039215686,-55) [0|0] "" Vector__XXX
 SG_ CP_a148_maxVelocity m148 : 52|12@1- (1.0002442598925256,0) [0|0] "" Vector__XXX
 SG_ CP_a151_pilotLowMax m151 : 52|12@1- (0.010503175378602833,-5.745236932095749) [0|0] "" Vector__XXX
 SG_ CP_a161_pilotLowMax m161 : 52|12@1- (0.010503175378602833,-5.745236932095749) [0|0] "" Vector__XXX
 SG_ CP_a008_AllMemory_warnings m8 : 51|1@1+ (1,0) [0|0] "" Vector__XXX
 SG_ CP_a037_latchSwitchState m37 : 51|1@1+ (1,0) [0|0] "" Vector__XXX
 SG_ CP_a065_proximityV m65 : 51|7@1+ (0.047244094488188976,0) [0|0] "" Vector__XXX
 SG_ CP_a097_ME_IMTS_DMA m97 : 51|1@1+ (1,0) [0|0] "" Vector__XXX
 SG_ CP_a118_sdpTaskMiaTime m118 : 51|6@1+ (100,0) [0|0] "" Vector__XXX
 SG_ CP_a008_RAMconst_Fault m8 : 50|1@1+ (1,0) [0|0] "" Vector__XXX
 SG_ CP_a041_hallSensorFiltered m41 : 50|10@1+ (0.004887487782,0) [0|0] "" Vector__XXX
 SG_ CP_a042_hallSensorFiltered m42 : 50|10@1+ (0.004887487782,0) [0|0] "" Vector__XXX
 SG_ CP_a054_inletID m54 : 50|3@1+ (1,0) [0|0] "" Vector__XXX
 SG_ CP_a065_uhfReceiverMIA m65 : 50|1@1+ (1,0) [0|0] "" Vector__XXX
 SG_ CP_a087_dcOutputCurrent m87 : 50|14@1- (0.0732421875,0) [0|0] "" Vector__XXX
 SG_ CP_a088_dcOutputCurrent m88 : 50|14@1- (0.0732421875,0) [0|0] "" Vector__XXX
 SG_ CP_a097_ME_IMTS_MRI m97 : 50|1@1+ (1,0) [0|0] "" Vector__XXX
 SG_ CP_a153_pcsLineChargeCurrent m153 : 50|9@1+ (0.1,0) [0|0] "" Vector__XXX
 SG_ CP_a154_pcsLineChargeCurrent m154 : 50|9@1+ (0.1,0) [0|0] "" Vector__XXX
 SG_ CP_a008_RAMconst_Warning m8 : 49|1@1+ (1,0) [0|0] "" Vector__XXX
 SG_ CP_a097_ME_IMTS_MTI m97 : 49|1@1+ (1,0) [0|0] "" Vector__XXX
 SG_ CP_a000_alertDataW2 m0 : 48|16@1+ (1,0) [0|0] "" Vector__XXX
 SG_ CP_a003_canErrorWord2 m3 : 48|16@1+ (1,0) [0|0] "" Vector__XXX
 SG_ CP_a004_cc2Voltage m4 : 48|14@1+ (0.001,0) [0|0] "" Vector__XXX
 SG_ CP_a008_FlashWarning m8 : 48|1@1+ (1,0) [0|0] "" Vector__XXX
 SG_ CP_a036_inletID m36 : 48|3@1+ (1,0) [0|0] "" Vector__XXX
 SG_ CP_a037_inletID m37 : 48|3@1+ (1,0) [0|0] "" Vector__XXX
 SG_ CP_a038_inletID m38 : 48|3@1+ (1,0) [0|0] "" Vector__XXX
 SG_ CP_a054_CP_proximity m54 : 48|2@1+ (1,0) [0|0] "" Vector__XXX
 SG_ CP_a068_hallSensorFiltered m68 : 48|10@1+ (0.004887487782,0) [0|0] "" Vector__XXX
 SG_ CP_a075_evccSocketErrRx m75 : 48|5@1+ (1,0) [0|0] "" Vector__XXX
 SG_ CP_a084_cc2Voltage m84 : 48|14@1+ (0.001,0) [0|0] "" Vector__XXX
 SG_ CP_a095_ambientTemp m95 : 48|8@1+ (0.8039215686,-55) [0|0] "" Vector__XXX
 SG_ CP_a097_ME_PS2_PIT_RTI m97 : 48|1@1+ (1,0) [0|0] "" Vector__XXX
 SG_ CP_a126_preventingSleepCount m126 : 48|10@1+ (1,0) [0|0] "" Vector__XXX
 SG_ CP_a165_maxSensedNoise m165 : 48|8@1+ (0.0003921568627450981,0) [0|0] "" Vector__XXX
 SG_ CP_a069_inductiveErrorUnderRange m69 : 47|1@1+ (1,0) [0|0] "" Vector__XXX
 SG_ CP_a097_ME_PS2_RTC_API m97 : 47|1@1+ (1,0) [0|0] "" Vector__XXX
 SG_ CP_a069_inductiveErrorOverRange m69 : 46|1@1+ (1,0) [0|0] "" Vector__XXX
 SG_ CP_a097_ME_PS2_eMIOS1 m97 : 46|1@1+ (1,0) [0|0] "" Vector__XXX
 SG_ CP_a010_pilotPWMdetected m10 : 45|1@1+ (1,0) [0|0] "" Vector__XXX
 SG_ CP_a069_inductiveErrorWatchdog m69 : 45|1@1+ (1,0) [0|0] "" Vector__XXX
 SG_ CP_a097_ME_PS2_eMIOS0 m97 : 45|1@1+ (1,0) [0|0] "" Vector__XXX
 SG_ CP_a118_evccTaskMiaTime m118 : 45|6@1+ (100,0) [0|0] "" Vector__XXX
 SG_ CP_a010_evseAccept m10 : 44|1@1+ (1,0) [0|0] "" Vector__XXX
 SG_ CP_a043_idleDoorPot m43 : 44|12@1+ (0.025,0) [0|0] "" Vector__XXX
 SG_ CP_a069_inductiveErrorAmplitude m69 : 44|1@1+ (1,0) [0|0] "" Vector__XXX
 SG_ CP_a073_ccs1AdapterBtnPress m73 : 44|1@1+ (1,0) [0|0] "" Vector__XXX
 SG_ CP_a076_doorCountsFiltered m76 : 44|12@1+ (0.025,0) [0|0] "" Vector__XXX
 SG_ CP_a097_ME_PS2_WKPU m97 : 44|1@1+ (1,0) [0|0] "" Vector__XXX
 SG_ CP_a120_chargeCurrent m120 : 44|8@1+ (5,0) [0|0] "" Vector__XXX
 SG_ CP_a152_maxPilotSwcanLow m152 : 44|9@1+ (0.02837573385518591,0) [0|0] "" Vector__XXX
 SG_ CP_a159_maxPilotSwcanLow m159 : 44|9@1+ (0.02837573385518591,0) [0|0] "" Vector__XXX
 SG_ CP_a162_maxPilotSwcanLow m162 : 44|9@1+ (0.02837573385518591,0) [0|0] "" Vector__XXX
 SG_ CP_a168_pilotHsdFaultLine m168 : 44|1@1+ (1,0) [0|0] "" Vector__XXX
 SG_ CP_a009_cover2State m9 : 43|3@1+ (1,0) [0|0] "" Vector__XXX
 SG_ CP_a065_pinTemperature2 m65 : 43|7@1+ (1.6141732283,-55) [0|0] "" Vector__XXX
 SG_ CP_a073_servicesNotSupported m73 : 43|1@1+ (1,0) [0|0] "" Vector__XXX
 SG_ CP_a075_evccSocketErrTx m75 : 43|5@1+ (1,0) [0|0] "" Vector__XXX
 SG_ CP_a097_ME_PS2_SIUL m97 : 43|1@1+ (1,0) [0|0] "" Vector__XXX
 SG_ CP_a163_cover2State m163 : 43|3@1+ (1,0) [0|0] "" Vector__XXX
 SG_ CP_a173_cover2State m173 : 43|3@1+ (1,0) [0|0] "" Vector__XXX
 SG_ CP_a073_emergencyShutdown m73 : 42|1@1+ (1,0) [0|0] "" Vector__XXX
 SG_ CP_a087_dTdtDcExpected m87 : 42|8@1+ (0.082,-10) [0|0] "" Vector__XXX
 SG_ CP_a088_dTdtDcExpected m88 : 42|8@1+ (0.082,-10) [0|0] "" Vector__XXX
 SG_ CP_a097_ME_PS1_I2C0 m97 : 42|1@1+ (1,0) [0|0] "" Vector__XXX
 SG_ CP_a148_presenceVoltage m148 : 42|10@1+ (0.004887585532746823,0) [0|0] "" Vector__XXX
 SG_ CP_a153_ambientTemp m153 : 42|8@1+ (0.8039215686,-55) [0|0] "" Vector__XXX
 SG_ CP_a154_ambientTemp m154 : 42|8@1+ (0.8039215686,-55) [0|0] "" Vector__XXX
 SG_ CP_a073_v2gCommsEstablished m73 : 41|1@1+ (1,0) [0|0] "" Vector__XXX
 SG_ CP_a075_initFailureType m75 : 41|2@1+ (1,0) [0|0] "" Vector__XXX
 SG_ CP_a097_ME_PS1_ADC0 m97 : 41|1@1+ (1,0) [0|0] "" Vector__XXX
 SG_ CP_a005_packCurrent m5 : 40|12@1+ (0.09768009768009768,0) [0|0] "" Vector__XXX
 SG_ CP_a009_cover1State m9 : 40|3@1+ (1,0) [0|0] "" Vector__XXX
 SG_ CP_a035_inletID m35 : 40|3@1+ (1,0) [0|0] "" Vector__XXX
 SG_ CP_a038_CP_apsVoltage m38 : 40|8@1+ (0.071568627,0) [0|0] "" Vector__XXX
 SG_ CP_a066_proximity m66 : 40|2@1+ (1,0) [0|0] "" Vector__XXX
 SG_ CP_a073_cpInternalStopChgRequest m73 : 40|1@1+ (1,0) [0|0] "" Vector__XXX
 SG_ CP_a075_evseEmergencyChgEnd m75 : 40|1@1+ (1,0) [0|0] "" Vector__XXX
 SG_ CP_a078_pinTemperature3 m78 : 40|8@1+ (0.8039215686,-55) [0|0] "" Vector__XXX
 SG_ CP_a079_pinTemperature3 m79 : 40|8@1+ (0.8039215686,-55) [0|0] "" Vector__XXX
 SG_ CP_a097_ME_PS0_FlexCAN5 m97 : 40|1@1+ (1,0) [0|0] "" Vector__XXX
 SG_ CP_a151_pilotLowMin m151 : 40|12@1- (0.010503175378602833,-5.745236932095749) [0|0] "" Vector__XXX
 SG_ CP_a160_buildConfigId m160 : 40|16@1+ (1,0) [0|0] "" Vector__XXX
 SG_ CP_a161_pilotLowMin m161 : 40|12@1- (0.010503175378602833,-5.745236932095749) [0|0] "" Vector__XXX
 SG_ CP_a163_cover1State m163 : 40|3@1+ (1,0) [0|0] "" Vector__XXX
 SG_ CP_a165_outOfBoundSamples m165 : 40|6@1+ (1,0) [0|0] "" Vector__XXX
 SG_ CP_a167_CP_doorId_intervalMin10s m167 : 40|8@1+ (0.0196078431372549,0) [0|0] "" Vector__XXX
 SG_ CP_a173_cover1State m173 : 40|3@1+ (1,0) [0|0] "" Vector__XXX
 SG_ CP_a073_evseShutdownRequested m73 : 39|1@1+ (1,0) [0|0] "" Vector__XXX
 SG_ CP_a097_ME_PS0_FlexCAN4 m97 : 39|1@1+ (1,0) [0|0] "" Vector__XXX
 SG_ CP_a118_teslaV2gTaskMiaTime m118 : 39|6@1+ (100,0) [0|0] "" Vector__XXX
 SG_ CP_a073_bmsShutdownRequested m73 : 38|1@1+ (1,0) [0|0] "" Vector__XXX
 SG_ CP_a097_ME_PS0_FlexCAN3 m97 : 38|1@1+ (1,0) [0|0] "" Vector__XXX
 SG_ CP_a073_commsFault m73 : 37|1@1+ (1,0) [0|0] "" Vector__XXX
 SG_ CP_a097_ME_PS0_FlexCAN2 m97 : 37|1@1+ (1,0) [0|0] "" Vector__XXX
 SG_ CP_a115_intReg3CrcEepromError m115 : 37|1@1+ (1,0) [0|0] "" Vector__XXX
 SG_ CP_a126_unknownDataCount m126 : 37|10@1+ (1,0) [0|0] "" Vector__XXX
 SG_ CP_a165_proxWiggleSource m165 : 37|3@1- (1,0) [0|0] "" Vector__XXX
 SG_ CP_a005_gbdcState m5 : 36|4@1+ (1,0) [0|0] "" Vector__XXX
 SG_ CP_a031_inductiveSensorFiltered m31 : 36|18@1+ (82.77924644182755,0) [0|0] "" Vector__XXX
 SG_ CP_a032_inductiveSensorFiltered m32 : 36|18@1+ (82.77924644182755,0) [0|0] "" Vector__XXX
 SG_ CP_a036_CP_apsVoltage m36 : 36|12@1+ (0.017094017094017096,0) [0|0] "" Vector__XXX
 SG_ CP_a037_CP_apsVoltage m37 : 36|12@1+ (0.017094017094017096,0) [0|0] "" Vector__XXX
 SG_ CP_a054_CP_apsVoltage m54 : 36|12@1+ (0.017094017094017096,0) [0|0] "" Vector__XXX
 SG_ CP_a065_pinTemperature1 m65 : 36|7@1+ (1.6141732283,-55) [0|0] "" Vector__XXX
 SG_ CP_a073_comboHandleNotPresent m73 : 36|1@1+ (1,0) [0|0] "" Vector__XXX
 SG_ CP_a097_ME_PS0_FlexCAN1 m97 : 36|1@1+ (1,0) [0|0] "" Vector__XXX
 SG_ CP_a115_intReg3FailSafeModeEnter m115 : 36|1@1+ (1,0) [0|0] "" Vector__XXX
 SG_ CP_a120_chargeVoltage m120 : 36|8@1+ (5,0) [0|0] "" Vector__XXX
 SG_ CP_a036_CP_latchEnableCmd m36 : 35|1@1+ (1,0) [0|0] "" Vector__XXX
 SG_ CP_a037_CP_latchEnableCmd m37 : 35|1@1+ (1,0) [0|0] "" Vector__XXX
 SG_ CP_a038_CP_latchEnableCmd m38 : 35|1@1+ (1,0) [0|0] "" Vector__XXX
 SG_ CP_a054_CP_latchEnableCmd m54 : 35|1@1+ (1,0) [0|0] "" Vector__XXX
 SG_ CP_a065_leds_failedBlue m65 : 35|1@1+ (1,0) [0|0] "" Vector__XXX
 SG_ CP_a097_ME_PS0_FlexCAN0 m97 : 35|1@1+ (1,0) [0|0] "" Vector__XXX
 SG_ CP_a115_intReg3SwError m115 : 35|1@1+ (1,0) [0|0] "" Vector__XXX
 SG_ CP_a152_minPilotSwcanHigh m152 : 35|9@1+ (0.02837573385518591,0) [0|0] "" Vector__XXX
 SG_ CP_a159_minPilotSwcanHigh m159 : 35|9@1+ (0.02837573385518591,0) [0|0] "" Vector__XXX
 SG_ CP_a162_minPilotSwcanHigh m162 : 35|9@1+ (0.02837573385518591,0) [0|0] "" Vector__XXX
 SG_ CP_a036_CHG_InsertEnable m36 : 34|1@1+ (1,0) [0|0] "" Vector__XXX
 SG_ CP_a037_CHG_InsertEnable m37 : 34|1@1+ (1,0) [0|0] "" Vector__XXX
 SG_ CP_a038_CHG_InsertEnable m38 : 34|1@1+ (1,0) [0|0] "" Vector__XXX
 SG_ CP_a054_CHG_InsertEnable m54 : 34|1@1+ (1,0) [0|0] "" Vector__XXX
 SG_ CP_a065_leds_failedGreen m65 : 34|1@1+ (1,0) [0|0] "" Vector__XXX
 SG_ CP_a087_dTdtDcActual m87 : 34|8@1+ (0.082,-10) [0|0] "" Vector__XXX
 SG_ CP_a088_dTdtDcActual m88 : 34|8@1+ (0.082,-10) [0|0] "" Vector__XXX
 SG_ CP_a097_ME_PS0_DSPI1 m97 : 34|1@1+ (1,0) [0|0] "" Vector__XXX
 SG_ CP_a115_intReg3SpiError m115 : 34|1@1+ (1,0) [0|0] "" Vector__XXX
 SG_ CP_a153_acPinTemp2 m153 : 34|8@1+ (0.8039215686,-55) [0|0] "" Vector__XXX
 SG_ CP_a154_acPinTemp2 m154 : 34|8@1+ (0.8039215686,-55) [0|0] "" Vector__XXX
 SG_ CP_a168_lvBusVoltage m168 : 34|10@1+ (0.019550342130987292,0) [0|0] "" Vector__XXX
 SG_ CP_a058_acRetryTimeoutS m58 : 33|15@1+ (1,0) [0|0] "" Vector__XXX
 SG_ CP_a065_leds_failedRed m65 : 33|1@1+ (1,0) [0|0] "" Vector__XXX
 SG_ CP_a097_ME_PS0_DSPI0 m97 : 33|1@1+ (1,0) [0|0] "" Vector__XXX
 SG_ CP_a115_intReg2ThermalShutdownWa m115 : 33|1@1+ (1,0) [0|0] "" Vector__XXX
 SG_ CP_a118_v2gTaskMiaTime m118 : 33|6@1+ (100,0) [0|0] "" Vector__XXX
 SG_ CP_a000_alertDataW1 m0 : 32|16@1+ (1,0) [0|0] "" Vector__XXX
 SG_ CP_a003_canErrorWord1 m3 : 32|16@1+ (1,0) [0|0] "" Vector__XXX
 SG_ CP_a004_cc1Voltage m4 : 32|14@1+ (0.001,0) [0|0] "" Vector__XXX
 SG_ CP_a008_data2 m8 : 32|16@1+ (1,0) [0|0] "" Vector__XXX
 SG_ CP_a010_pilotLow m10 : 32|12@1- (0.008,0) [0|0] "" Vector__XXX
 SG_ CP_a036_latchState m36 : 32|2@1+ (1,0) [0|0] "" Vector__XXX
 SG_ CP_a037_latchState m37 : 32|2@1+ (1,0) [0|0] "" Vector__XXX
 SG_ CP_a038_latchState m38 : 32|2@1+ (1,0) [0|0] "" Vector__XXX
 SG_ CP_a041_inductiveSensorFiltered m41 : 32|18@1+ (82.77924644182755,0) [0|0] "" Vector__XXX
 SG_ CP_a042_inductiveSensorFiltered m42 : 32|18@1+ (82.77924644182755,0) [0|0] "" Vector__XXX
 SG_ CP_a043_doorVelocity m43 : 32|12@1- (0.5,0) [0|0] "" Vector__XXX
 SG_ CP_a050_binaryCurrentProfile m50 : 32|30@1+ (1,0) [0|0] "" Vector__XXX
 SG_ CP_a054_latchState m54 : 32|2@1+ (1,0) [0|0] "" Vector__XXX
 SG_ CP_a058_acNumRetries m58 : 32|1@1+ (1,0) [0|0] "" Vector__XXX
 SG_ CP_a061_timeMsInControlState m61 : 32|16@1+ (1,0) [0|0] "" Vector__XXX
 SG_ CP_a065_latch_failedEngage m65 : 32|1@1+ (1,0) [0|0] "" Vector__XXX
 SG_ CP_a067_cc2Voltage m67 : 32|14@1+ (0.001,0) [0|0] "" Vector__XXX
 SG_ CP_a073_ccsShutdownReason m73 : 32|4@1+ (1,0) [0|0] "" Vector__XXX
 SG_ CP_a074_evseMeasuredAtten m74 : 32|8@1+ (1,0) [0|0] "" Vector__XXX
 SG_ CP_a075_evseMeasuredAtten m75 : 32|8@1+ (1,0) [0|0] "" Vector__XXX
 SG_ CP_a078_pinTemperature2 m78 : 32|8@1+ (0.8039215686,-55) [0|0] "" Vector__XXX
 SG_ CP_a079_pinTemperature2 m79 : 32|8@1+ (0.8039215686,-55) [0|0] "" Vector__XXX
 SG_ CP_a081_exceptionRegisterData m81 : 32|32@1+ (1,0) [0|0] "" Vector__XXX
 SG_ CP_a083_traceDump m83 : 32|32@1+ (1,0) [0|0] "" Vector__XXX
 SG_ CP_a084_cc1Voltage m84 : 32|14@1+ (0.001,0) [0|0] "" Vector__XXX
 SG_ CP_a095_dcOutputCurrent m95 : 32|13@1- (1,0) [0|0] "" Vector__XXX
 SG_ CP_a097_ME_IS_MTC m97 : 32|1@1+ (1,0) [0|0] "" Vector__XXX
 SG_ CP_a100_inletID m100 : 32|3@1+ (1,0) [0|0] "" Vector__XXX
 SG_ CP_a106_timeMsInControlState m106 : 32|16@1+ (1,0) [0|0] "" Vector__XXX
 SG_ CP_a110_thermalVelocity m110 : 32|10@1- (0.15748,0) [0|0] "" Vector__XXX
 SG_ CP_a115_intReg2ThermalShutdown m115 : 32|1@1+ (1,0) [0|0] "" Vector__XXX
 SG_ CP_a123_latchState m123 : 32|2@1+ (1,0) [0|0] "" Vector__XXX
 SG_ CP_a136_evseMeasuredAtten m136 : 32|8@1+ (1,0) [0|0] "" Vector__XXX
 SG_ CP_a137_state m137 : 32|3@1+ (1,0) [0|0] "" Vector__XXX
 SG_ CP_a142_cc2Voltage m142 : 32|14@1+ (0.001,0) [0|0] "" Vector__XXX
 SG_ CP_a148_maxCurrent m148 : 32|10@1+ (0.004887585532746823,0) [0|0] "" Vector__XXX
 SG_ CP_a149_proximityState m149 : 32|2@1+ (1,0) [0|0] "" Vector__XXX
 SG_ CP_a165_edgeCounts m165 : 32|5@1+ (1,0) [0|0] "" Vector__XXX
 SG_ CP_a167_CP_doorId_intervalMax10s m167 : 32|8@1+ (0.0196078431372549,0) [0|0] "" Vector__XXX
 SG_ CP_a202_evseMeasuredAtten m202 : 32|8@1+ (1,0) [0|0] "" Vector__XXX
 SG_ CP_a205_presenceVoltage m205 : 32|10@1+ (0.004887585532746823,0) [0|0] "" Vector__XXX
 SG_ CP_a065_latch_failedDisengage m65 : 31|1@1+ (1,0) [0|0] "" Vector__XXX
 SG_ CP_a097_ME_IS_SAFE m97 : 31|1@1+ (1,0) [0|0] "" Vector__XXX
 SG_ CP_a115_intReg2VccUnderVoltage m115 : 31|1@1+ (1,0) [0|0] "" Vector__XXX
 SG_ CP_a205_bldcTachIsInvalid m205 : 31|1@1+ (1,0) [0|0] "" Vector__XXX
 SG_ CP_a058_CP_proximity m58 : 30|2@1+ (1,0) [0|0] "" Vector__XXX
 SG_ CP_a097_ME_IS_IMODE m97 : 30|1@1+ (1,0) [0|0] "" Vector__XXX
 SG_ CP_a115_intReg2VioUnderVoltage m115 : 30|1@1+ (1,0) [0|0] "" Vector__XXX
 SG_ CP_a118_evccState m118 : 30|3@1+ (1,0) [0|0] "" Vector__XXX
 SG_ CP_a068_inductiveSensorFiltered m68 : 29|18@1+ (82.77924644182755,0) [0|0] "" Vector__XXX
 SG_ CP_a097_ME_IS_ICONF m97 : 29|1@1+ (1,0) [0|0] "" Vector__XXX
 SG_ CP_a115_intReg2VsupUnderVoltage m115 : 29|1@1+ (1,0) [0|0] "" Vector__XXX
 SG_ CP_a205_bldcMotorState m205 : 29|2@1+ (1,0) [0|0] "" Vector__XXX
 SG_ CP_a003_canErrorType m3 : 28|4@1+ (1,0) [0|0] "" Vector__XXX
 SG_ CP_a009_cover2OpenCounts m9 : 28|12@1+ (0.025,0) [0|0] "" Vector__XXX
 SG_ CP_a058_latchState m58 : 28|2@1+ (1,0) [0|0] "" Vector__XXX
 SG_ CP_a066_pilotLow m66 : 28|12@1- (0.008,0) [0|0] "" Vector__XXX
 SG_ CP_a068_doorClosed m68 : 28|1@1+ (1,0) [0|0] "" Vector__XXX
 SG_ CP_a097_modeTransitionStatus m97 : 28|1@1+ (1,0) [0|0] "" Vector__XXX
 SG_ CP_a115_intReg2PowerOnEvent m115 : 28|1@1+ (1,0) [0|0] "" Vector__XXX
 SG_ CP_a149_iecPilotState m149 : 28|4@1+ (1,0) [0|0] "" Vector__XXX
 SG_ CP_a151_pilotHighMax m151 : 28|12@1+ (0.003540903540903541,0) [0|0] "" Vector__XXX
 SG_ CP_a161_pilotHighMax m161 : 28|12@1+ (0.003540903540903541,0) [0|0] "" Vector__XXX
 SG_ CP_a163_cover2OpenCounts m163 : 28|12@1+ (0.025,0) [0|0] "" Vector__XXX
 SG_ CP_a166_hvFaultLineCpAppliedOutp m166 : 28|1@1+ (1,0) [0|0] "" Vector__XXX
 SG_ CP_a173_cover2OpenCounts m173 : 28|12@1+ (0.025,0) [0|0] "" Vector__XXX
 SG_ CP_a182_txRetryCounter m182 : 28|2@1+ (1,0) [0|0] "" Vector__XXX
 SG_ CP_a205_doorPositionEstimationSu m205 : 28|1@1+ (1,0) [0|0] "" Vector__XXX
 SG_ CP_a005_cc2Voltage m5 : 27|9@1+ (0.009784735812133072,0) [0|0] "" Vector__XXX
 SG_ CP_a073_ccsEnergyType m73 : 27|2@1+ (1,0) [0|0] "" Vector__XXX
 SG_ CP_a115_intReg2SleepModeStatusFl m115 : 27|1@1+ (1,0) [0|0] "" Vector__XXX
 SG_ CP_a118_teslaV2gState m118 : 27|3@1+ (1,0) [0|0] "" Vector__XXX
 SG_ CP_a126_selfTestCount m126 : 27|10@1+ (1,0) [0|0] "" Vector__XXX
 SG_ CP_a165_teslaEvseConnected m165 : 27|1@1+ (1,0) [0|0] "" Vector__XXX
 SG_ CP_a050_minLatchCurrentBelowThre m50 : 26|6@1+ (0.0007936507936507937,0) [0|0] "" Vector__XXX
 SG_ CP_a087_dcPinTempExpected m87 : 26|8@1+ (0.8039215686,-55) [0|0] "" Vector__XXX
 SG_ CP_a088_dcPinTempExpected m88 : 26|8@1+ (0.8039215686,-55) [0|0] "" Vector__XXX
 SG_ CP_a115_intReg1CanBusStuckDomina m115 : 26|1@1+ (1,0) [0|0] "" Vector__XXX
 SG_ CP_a120_newProximtyV m120 : 26|10@1+ (0.004887585532746823,0) [0|0] "" Vector__XXX
 SG_ CP_a152_maxPilotSwcanHigh m152 : 26|9@1+ (0.02837573385518591,0) [0|0] "" Vector__XXX
 SG_ CP_a153_acPinTemp1 m153 : 26|8@1+ (0.8039215686,-55) [0|0] "" Vector__XXX
 SG_ CP_a154_acPinTemp1 m154 : 26|8@1+ (0.8039215686,-55) [0|0] "" Vector__XXX
 SG_ CP_a159_maxPilotSwcanHigh m159 : 26|9@1+ (0.02837573385518591,0) [0|0] "" Vector__XXX
 SG_ CP_a162_maxPilotSwcanHigh m162 : 26|9@1+ (0.02837573385518591,0) [0|0] "" Vector__XXX
 SG_ CP_a075_failedResponseCode m75 : 25|1@1+ (1,0) [0|0] "" Vector__XXX
 SG_ CP_a115_intReg1CanBusInactiveAsl m115 : 25|1@1+ (1,0) [0|0] "" Vector__XXX
 SG_ CP_a149_pilotState m149 : 25|3@1+ (1,0) [0|0] "" Vector__XXX
 SG_ CP_a006_BMS_evsePackInfo_MIA m6 : 24|1@1+ (1,0) [0|0] "" Vector__XXX
 SG_ CP_a023_chargeAttempts m23 : 24|3@1+ (1,0) [0|0] "" Vector__XXX
 SG_ CP_a030_busOffOccurences m30 : 24|32@1+ (1,0) [0|0] "" Vector__XXX
 SG_ CP_a031_doorCountsFiltered m31 : 24|12@1+ (0.025,0) [0|0] "" Vector__XXX
 SG_ CP_a032_doorCountsFiltered m32 : 24|12@1+ (0.025,0) [0|0] "" Vector__XXX
 SG_ CP_a035_latchOffset m35 : 24|16@1- (0.00305185095,0) [0|0] "" Vector__XXX
 SG_ CP_a056_packCurrent m56 : 24|16@1- (0.1,0) [0|0] "" Vector__XXX
 SG_ CP_a058_FC_status m58 : 24|4@1+ (1,0) [0|0] "" Vector__XXX
 SG_ CP_a061_chipState m61 : 24|3@1+ (1,0) [0|0] "" Vector__XXX
 SG_ CP_a065_doorPotFiltered m65 : 24|7@1+ (0.7874015748031497,0) [0|0] "" Vector__XXX
 SG_ CP_a070_i2cIBSR m70 : 24|8@1+ (1,0) [0|0] "" Vector__XXX
 SG_ CP_a072_preChargeExpired m72 : 24|1@1+ (1,0) [0|0] "" Vector__XXX
 SG_ CP_a073_ccsAcState m73 : 24|3@1+ (1,0) [0|0] "" Vector__XXX
 SG_ CP_a074_sdpNoDiscoveryResponse m74 : 24|1@1+ (1,0) [0|0] "" Vector__XXX
 SG_ CP_a075_exiUnpackFailed m75 : 24|1@1+ (1,0) [0|0] "" Vector__XXX
 SG_ CP_a078_pinTemperature1 m78 : 24|8@1+ (0.8039215686,-55) [0|0] "" Vector__XXX
 SG_ CP_a079_pinTemperature1 m79 : 24|8@1+ (0.8039215686,-55) [0|0] "" Vector__XXX
 SG_ CP_a081_exceptionRegisterIndex m81 : 24|3@1+ (1,0) [0|0] "" Vector__XXX
 SG_ CP_a083_traceIndex m83 : 24|4@1+ (1,0) [0|0] "" Vector__XXX
 SG_ CP_a085_dcPinTemp m85 : 24|8@1+ (0.8039215686,-55) [0|0] "" Vector__XXX
 SG_ CP_a096_pilotWakeData m96 : 24|32@1+ (1,0) [0|0] "" Vector__XXX
 SG_ CP_a097_requestedMode m97 : 24|4@1+ (1,0) [0|0] "" Vector__XXX
 SG_ CP_a106_chipState m106 : 24|3@1+ (1,0) [0|0] "" Vector__XXX
 SG_ CP_a109_thermistorTemp m109 : 24|8@1+ (0.8039215686,-55) [0|0] "" Vector__XXX
 SG_ CP_a110_thermistorTemp m110 : 24|8@1+ (0.8039215686,-55) [0|0] "" Vector__XXX
 SG_ CP_a111_VC_tempAmbientFiltered m111 : 24|8@1+ (0.5,-40) [0|0] "" Vector__XXX
 SG_ CP_a113_heaterCurrent m113 : 24|12@1+ (0.0025,0) [0|0] "" Vector__XXX
 SG_ CP_a114_responseCode m114 : 24|5@1+ (1,0) [0|0] "" Vector__XXX
 SG_ CP_a115_intReg1CanBusInactiveAwa m115 : 24|1@1+ (1,0) [0|0] "" Vector__XXX
 SG_ CP_a117_averageError m117 : 24|8@1+ (0.8039215686,-55) [0|0] "" Vector__XXX
 SG_ CP_a118_ccsManagerState m118 : 24|3@1+ (1,0) [0|0] "" Vector__XXX
 SG_ CP_a122_plcModemErrData m122 : 24|32@1+ (1,0) [0|0] "" Vector__XXX
 SG_ CP_a124_ivledVoltage m124 : 24|8@1+ (0.01968504,0) [0|0] "" Vector__XXX
 SG_ CP_a135_evseMeasuredAtten m135 : 24|8@1+ (1,0) [0|0] "" Vector__XXX
 SG_ CP_a136_pilotState m136 : 24|3@1+ (1,0) [0|0] "" Vector__XXX
 SG_ CP_a137_socketErr m137 : 24|8@1- (1,0) [0|0] "" Vector__XXX
 SG_ CP_a160_evseOutputDcCurrent m160 : 24|15@1- (0.125,0) [0|0] "" Vector__XXX
 SG_ CP_a164_minInternalPinTemp m164 : 24|8@1+ (0.8039215686,-55) [0|0] "" Vector__XXX
 SG_ CP_a165_chargeProtocol m165 : 24|3@1+ (1,0) [0|0] "" Vector__XXX
 SG_ CP_a167_CP_doorIdCurrentVoltage m167 : 24|8@1+ (0.0196078431372549,0) [0|0] "" Vector__XXX
 SG_ CP_a168_pilotHigh m168 : 24|10@1+ (0.019550342130987292,0) [0|0] "" Vector__XXX
 SG_ CP_a177_vehicleVersion m177 : 24|5@1+ (1,0) [0|0] "" Vector__XXX
 SG_ CP_a179_mbedTlsError m179 : 24|32@1- (1,0) [0|0] "" Vector__XXX
 SG_ CP_a182_receivedPncdMessageTag m182 : 24|4@1+ (1,0) [0|0] "" Vector__XXX
 SG_ CP_a185_responseCode m185 : 24|5@1+ (1,0) [0|0] "" Vector__XXX
 SG_ CP_a187_taskStackUsage m187 : 24|7@1+ (0.7874015748031497,0) [0|0] "" Vector__XXX
 SG_ CP_a202_sdpNoDiscoveryResponse m202 : 24|1@1+ (1,0) [0|0] "" Vector__XXX
 SG_ CP_a204_evseMeasuredAtten m204 : 24|8@1+ (1,0) [0|0] "" Vector__XXX
 SG_ CP_a006_BMS_bmbMinMax_MIA m6 : 23|1@1+ (1,0) [0|0] "" Vector__XXX
 SG_ CP_a072_cableCheckExpired m72 : 23|1@1+ (1,0) [0|0] "" Vector__XXX
 SG_ CP_a115_intReg1FrameOverflow m115 : 23|1@1+ (1,0) [0|0] "" Vector__XXX
 SG_ CP_a006_BMS_v2xInfo_MIA m6 : 22|1@1+ (1,0) [0|0] "" Vector__XXX
 SG_ CP_a007_taskBldcControlStarved m7 : 22|1@1+ (1,0) [0|0] "" Vector__XXX
 SG_ CP_a046_CC_chgStatus_flag m46 : 22|1@1+ (1,0) [0|0] "" Vector__XXX
 SG_ CP_a048_UI_gridFormControl_MIA m48 : 22|1@1+ (1,0) [0|0] "" Vector__XXX
 SG_ CP_a065_door_buttonPressed m65 : 22|1@1+ (1,0) [0|0] "" Vector__XXX
 SG_ CP_a072_commsSetupExpired m72 : 22|1@1+ (1,0) [0|0] "" Vector__XXX
 SG_ CP_a115_intReg1WakeError m115 : 22|1@1+ (1,0) [0|0] "" Vector__XXX
 SG_ CP_a006_BMS_socStatus_MIA m6 : 21|1@1+ (1,0) [0|0] "" Vector__XXX
 SG_ CP_a007_taskUHFStarved m7 : 21|1@1+ (1,0) [0|0] "" Vector__XXX
 SG_ CP_a029_CP_chargeDoorOpen m29 : 21|1@1+ (1,0) [0|0] "" Vector__XXX
 SG_ CP_a046_FC_maxLimitsHighPower m46 : 21|1@1+ (1,0) [0|0] "" Vector__XXX
 SG_ CP_a048_VEH_billing_MIA m48 : 21|1@1+ (1,0) [0|0] "" Vector__XXX
 SG_ CP_a065_door_presenceFailClose m65 : 21|1@1+ (1,0) [0|0] "" Vector__XXX
 SG_ CP_a072_readyToChargeExpired m72 : 21|1@1+ (1,0) [0|0] "" Vector__XXX
 SG_ CP_a115_intReg1LocalWakeUp m115 : 21|1@1+ (1,0) [0|0] "" Vector__XXX
 SG_ CP_a138_CP_proximity m138 : 21|2@1+ (1,0) [0|0] "" Vector__XXX
 SG_ CP_a152_swcanLowMismatchCount m152 : 21|5@1+ (1,0) [0|0] "" Vector__XXX
 SG_ CP_a159_swcanLowMismatchCount m159 : 21|5@1+ (1,0) [0|0] "" Vector__XXX
 SG_ CP_a162_swcanLowMismatchCount m162 : 21|5@1+ (1,0) [0|0] "" Vector__XXX
 SG_ CP_a006_BMS_kwhCounter_MIA m6 : 20|1@1+ (1,0) [0|0] "" Vector__XXX
 SG_ CP_a007_taskI2CStarved m7 : 20|1@1+ (1,0) [0|0] "" Vector__XXX
 SG_ CP_a023_failureReason m23 : 20|2@1+ (1,0) [0|0] "" Vector__XXX
 SG_ CP_a046_FC_limitsHighPower_flag m46 : 20|1@1+ (1,0) [0|0] "" Vector__XXX
 SG_ CP_a048_UI_hvacRequest_MIA m48 : 20|1@1+ (1,0) [0|0] "" Vector__XXX
 SG_ CP_a056_CP_proximity m56 : 20|2@1+ (1,0) [0|0] "" Vector__XXX
 SG_ CP_a061_lastControlState m61 : 20|4@1+ (1,0) [0|0] "" Vector__XXX
 SG_ CP_a062_FC_type m62 : 20|3@1+ (1,0) [0|0] "" Vector__XXX
 SG_ CP_a063_FC_type m63 : 20|3@1+ (1,0) [0|0] "" Vector__XXX
 SG_ CP_a065_door_presenceFailOpen m65 : 20|1@1+ (1,0) [0|0] "" Vector__XXX
 SG_ CP_a074_slacErrorCode m74 : 20|4@1+ (1,0) [0|0] "" Vector__XXX
 SG_ CP_a097_targetMode m97 : 20|4@1+ (1,0) [0|0] "" Vector__XXX
 SG_ CP_a106_lastControlState m106 : 20|4@1+ (1,0) [0|0] "" Vector__XXX
 SG_ CP_a115_intReg1WakeupEvent m115 : 20|1@1+ (1,0) [0|0] "" Vector__XXX
 SG_ CP_a118_sdpState m118 : 20|3@1+ (1,0) [0|0] "" Vector__XXX
 SG_ CP_a165_cpPowerTransferStatus m165 : 20|3@1+ (1,0) [0|0] "" Vector__XXX
 SG_ CP_a182_expectedPncdMessageTag m182 : 20|4@1+ (1,0) [0|0] "" Vector__XXX
 SG_ CP_a202_slacErrorCode m202 : 20|4@1+ (1,0) [0|0] "" Vector__XXX
 SG_ CP_a006_BMS_hvPackStatus_MIA m6 : 19|1@1+ (1,0) [0|0] "" Vector__XXX
 SG_ CP_a007_task1000HzStarved m7 : 19|1@1+ (1,0) [0|0] "" Vector__XXX
 SG_ CP_a010_pilotHigh m10 : 19|12@1- (0.008,0) [0|0] "" Vector__XXX
 SG_ CP_a029_CP_proximity m29 : 19|2@1+ (1,0) [0|0] "" Vector__XXX
 SG_ CP_a043_doorPotFiltered m43 : 19|12@1+ (0.025,0) [0|0] "" Vector__XXX
 SG_ CP_a046_FC_statusHighPower_flag m46 : 19|1@1+ (1,0) [0|0] "" Vector__XXX
 SG_ CP_a047_vehNm_MIA m47 : 19|1@1+ (1,0) [0|0] "" Vector__XXX
 SG_ CP_a048_UI_vehicleModes_MIA m48 : 19|1@1+ (1,0) [0|0] "" Vector__XXX
 SG_ CP_a056_CP_latchEnableCmd m56 : 19|1@1+ (1,0) [0|0] "" Vector__XXX
 SG_ CP_a058_CC_pilot m58 : 19|2@1+ (1,0) [0|0] "" Vector__XXX
 SG_ CP_a060_PCS2_v2xInfo2_MIA m60 : 19|1@1+ (1,0) [0|0] "" Vector__XXX
 SG_ CP_a065_door_failedClose m65 : 19|1@1+ (1,0) [0|0] "" Vector__XXX
 SG_ CP_a073_ccsDcState m73 : 19|4@1+ (1,0) [0|0] "" Vector__XXX
 SG_ CP_a075_currentMessage m75 : 19|5@1+ (1,0) [0|0] "" Vector__XXX
 SG_ CP_a081_exceptionRegisterType m81 : 19|3@1+ (1,0) [0|0] "" Vector__XXX
 SG_ CP_a090_ccsDcState m90 : 19|4@1+ (1,0) [0|0] "" Vector__XXX
 SG_ CP_a093_interruptCauseRegError m93 : 19|1@1+ (1,0) [0|0] "" Vector__XXX
 SG_ CP_a096_pilotWakeDataType m96 : 19|3@1+ (1,0) [0|0] "" Vector__XXX
 SG_ CP_a115_intReg1WatchdogTrip m115 : 19|1@1+ (1,0) [0|0] "" Vector__XXX
 SG_ CP_a116_thermistorsOpenCircuit m116 : 19|1@1+ (1,0) [0|0] "" Vector__XXX
 SG_ CP_a119_slacState m119 : 19|4@1+ (1,0) [0|0] "" Vector__XXX
 SG_ CP_a135_pilotState m135 : 19|3@1+ (1,0) [0|0] "" Vector__XXX
 SG_ CP_a136_sdpErr m136 : 19|3@1+ (1,0) [0|0] "" Vector__XXX
 SG_ CP_a138_latchState m138 : 19|2@1+ (1,0) [0|0] "" Vector__XXX
 SG_ CP_a148_doorPosition m148 : 19|12@1+ (0.02442002442002442,0) [0|0] "" Vector__XXX
 SG_ CP_a160_fcBrand m160 : 19|1@1+ (1,0) [0|0] "" Vector__XXX
 SG_ CP_a168_pilotPowerState m168 : 19|4@1+ (1,0) [0|0] "" Vector__XXX
 SG_ CP_a178_faultType m178 : 19|3@1+ (1,0) [0|0] "" Vector__XXX
 SG_ CP_a204_pilotState m204 : 19|3@1+ (1,0) [0|0] "" Vector__XXX
 SG_ CP_a006_BMS_dcChargeLimits_MIA m6 : 18|1@1+ (1,0) [0|0] "" Vector__XXX
 SG_ CP_a007_task100HzStarved m7 : 18|1@1+ (1,0) [0|0] "" Vector__XXX
 SG_ CP_a010_voltageValid m10 : 18|1@1+ (1,0) [0|0] "" Vector__XXX
 SG_ CP_a030_busOffData m30 : 18|1@1+ (1,0) [0|0] "" Vector__XXX
 SG_ CP_a035_stateLeverMovedFrom m35 : 18|2@1+ (1,0) [0|0] "" Vector__XXX
 SG_ CP_a043_outOfRangeFlag m43 : 18|1@1+ (1,0) [0|0] "" Vector__XXX
 SG_ CP_a046_FC_maxLimits_flag m46 : 18|1@1+ (1,0) [0|0] "" Vector__XXX
 SG_ CP_a047_sensors_MIA m47 : 18|1@1+ (1,0) [0|0] "" Vector__XXX
 SG_ CP_a048_UI_status_MIA m48 : 18|1@1+ (1,0) [0|0] "" Vector__XXX
 SG_ CP_a050_maxLatchCurrentSeen m50 : 18|8@1+ (0.0007843137254901962,0) [0|0] "" Vector__XXX
 SG_ CP_a056_CHG_InsertEnable m56 : 18|1@1+ (1,0) [0|0] "" Vector__XXX
 SG_ CP_a060_PCS2_v2xInfo_MIA m60 : 18|1@1+ (1,0) [0|0] "" Vector__XXX
 SG_ CP_a065_door_failedOpen m65 : 18|1@1+ (1,0) [0|0] "" Vector__XXX
 SG_ CP_a077_macsMatching m77 : 18|1@1+ (1,0) [0|0] "" Vector__XXX
 SG_ CP_a087_dcPinTempActual m87 : 18|8@1+ (0.8039215686,-55) [0|0] "" Vector__XXX
 SG_ CP_a088_dcPinTempActual m88 : 18|8@1+ (0.8039215686,-55) [0|0] "" Vector__XXX
 SG_ CP_a089_plcModemPopulated m89 : 18|1@1+ (1,0) [0|0] "" Vector__XXX
 SG_ CP_a096_pilotActiveUponSleep m96 : 18|1@1+ (1,0) [0|0] "" Vector__XXX
 SG_ CP_a098_CP_proximityLast m98 : 18|2@1+ (1,0) [0|0] "" Vector__XXX
 SG_ CP_a099_pilot m99 : 18|3@1+ (1,0) [0|0] "" Vector__XXX
 SG_ CP_a100_inletHarnessIdV m100 : 18|12@1+ (0.001221001221001221,0) [0|0] "" Vector__XXX
 SG_ CP_a105_inductiveSensorReset m105 : 18|1@1+ (1,0) [0|0] "" Vector__XXX
 SG_ CP_a116_temperatureSensorMismatc m116 : 18|1@1+ (1,0) [0|0] "" Vector__XXX
 SG_ CP_a139_CP_proximity m139 : 18|2@1+ (1,0) [0|0] "" Vector__XXX
 SG_ CP_a140_CP_proximity m140 : 18|2@1+ (1,0) [0|0] "" Vector__XXX
 SG_ CP_a141_CP_proximity m141 : 18|2@1+ (1,0) [0|0] "" Vector__XXX
 SG_ CP_a150_state m150 : 18|2@1+ (1,0) [0|0] "" Vector__XXX
 SG_ CP_a166_hvFaultLineVoltage m166 : 18|10@1+ (0.004550576735092864,0) [0|0] "" Vector__XXX
 SG_ CP_a178_evccCommsDown m178 : 18|1@1+ (1,0) [0|0] "" Vector__XXX
 SG_ CP_a183_emaidSize m183 : 18|6@1+ (1,0) [0|0] "" Vector__XXX
 SG_ CP_a006_BMS_chargeStatus_MIA m6 : 17|1@1+ (1,0) [0|0] "" Vector__XXX
 SG_ CP_a007_task10HzStarved m7 : 17|1@1+ (1,0) [0|0] "" Vector__XXX
 SG_ CP_a010_widthValid m10 : 17|1@1+ (1,0) [0|0] "" Vector__XXX
 SG_ CP_a013_GTW_carConfig_MIA m13 : 17|1@1+ (1,0) [0|0] "" Vector__XXX
 SG_ CP_a028_hardlineEnable m28 : 17|1@1+ (1,0) [0|0] "" Vector__XXX
 SG_ CP_a043_wrongDirectionFlag m43 : 17|1@1+ (1,0) [0|0] "" Vector__XXX
 SG_ CP_a045_VCSEC_requests_MIA m45 : 17|1@1+ (1,0) [0|0] "" Vector__XXX
 SG_ CP_a046_FC_limits_flag m46 : 17|1@1+ (1,0) [0|0] "" Vector__XXX
 SG_ CP_a047_LVPowerState_MIA m47 : 17|1@1+ (1,0) [0|0] "" Vector__XXX
 SG_ CP_a048_UI_range_MIA m48 : 17|1@1+ (1,0) [0|0] "" Vector__XXX
 SG_ CP_a050_latch2NotConnected m50 : 17|1@1+ (1,0) [0|0] "" Vector__XXX
 SG_ CP_a060_PCS_chgLineStatus_MIA m60 : 17|1@1+ (1,0) [0|0] "" Vector__XXX
 SG_ CP_a065_door_failedCinch m65 : 17|1@1+ (1,0) [0|0] "" Vector__XXX
 SG_ CP_a077_mac2Invalid m77 : 17|1@1+ (1,0) [0|0] "" Vector__XXX
 SG_ CP_a087_dTdtMeasuredTooHigh m87 : 17|1@1+ (1,0) [0|0] "" Vector__XXX
 SG_ CP_a088_dTdtMeasuredTooLow m88 : 17|1@1+ (1,0) [0|0] "" Vector__XXX
 SG_ CP_a096_cableConnected m96 : 17|1@1+ (1,0) [0|0] "" Vector__XXX
 SG_ CP_a105_i2c_sda_gpdi m105 : 17|1@1+ (1,0) [0|0] "" Vector__XXX
 SG_ CP_a116_heaterDetected m116 : 17|1@1+ (1,0) [0|0] "" Vector__XXX
 SG_ CP_a126_handleFoundCount m126 : 17|10@1+ (1,0) [0|0] "" Vector__XXX
 SG_ CP_a128_pcsInterface_MIA m128 : 17|1@1+ (1,0) [0|0] "" Vector__XXX
 SG_ CP_a144_nvmBuffError m144 : 17|1@1+ (1,0) [0|0] "" Vector__XXX
 SG_ CP_a166_hvFaultLineDebouncedStat m166 : 17|1@1+ (1,0) [0|0] "" Vector__XXX
 SG_ CP_a178_sdpFailed m178 : 17|1@1+ (1,0) [0|0] "" Vector__XXX
 SG_ CP_a000_alertDataW0 m0 : 16|16@1+ (1,0) [0|0] "" Vector__XXX
 SG_ CP_a003_canAddress m3 : 16|12@1+ (1,0) [0|0] "" Vector__XXX
 SG_ CP_a004_proximityV m4 : 16|16@1+ (0.0001,0) [0|0] "" Vector__XXX
 SG_ CP_a005_cc1Voltage m5 : 16|11@1+ (0.006497313141182218,0) [0|0] "" Vector__XXX
 SG_ CP_a006_BMS_FC_limits_MIA m6 : 16|1@1+ (1,0) [0|0] "" Vector__XXX
 SG_ CP_a007_task1HzStarved m7 : 16|1@1+ (1,0) [0|0] "" Vector__XXX
 SG_ CP_a008_data1 m8 : 16|16@1+ (1,0) [0|0] "" Vector__XXX
 SG_ CP_a009_cover1OpenCounts m9 : 16|12@1+ (0.025,0) [0|0] "" Vector__XXX
 SG_ CP_a010_periodValid m10 : 16|1@1+ (1,0) [0|0] "" Vector__XXX
 SG_ CP_a011_eepromErrorType m11 : 16|3@1+ (1,0) [0|0] "" Vector__XXX
 SG_ CP_a013_GTW_vin_MIA m13 : 16|1@1+ (1,0) [0|0] "" Vector__XXX
 SG_ CP_a015_apsVoltageOV m15 : 16|8@1+ (0.071285156,0) [0|0] "" Vector__XXX
 SG_ CP_a016_apsVoltageUV m16 : 16|8@1+ (0.071285156,0) [0|0] "" Vector__XXX
 SG_ CP_a017_5V_VoltageOV m17 : 16|8@1+ (0.02352539,0) [0|0] "" Vector__XXX
 SG_ CP_a018_5V_VoltageUV m18 : 16|8@1+ (0.02352539,0) [0|0] "" Vector__XXX
 SG_ CP_a019_3_3V_VoltageOV m19 : 16|8@1+ (0.02352539,0) [0|0] "" Vector__XXX
 SG_ CP_a020_3_3V_VoltageUV m20 : 16|8@1+ (0.02352539,0) [0|0] "" Vector__XXX
 SG_ CP_a021_0V_VoltageOV m21 : 16|8@1+ (0.012890625,0) [0|0] "" Vector__XXX
 SG_ CP_a022_0V_VoltageUV m22 : 16|8@1+ (0.012890625,0) [0|0] "" Vector__XXX
 SG_ CP_a023_stopChargeReason m23 : 16|4@1+ (1,0) [0|0] "" Vector__XXX
 SG_ CP_a028_canEnable m28 : 16|1@1+ (1,0) [0|0] "" Vector__XXX
 SG_ CP_a029_CP_pilot m29 : 16|3@1+ (1,0) [0|0] "" Vector__XXX
 SG_ CP_a030_busOffIndex m30 : 16|2@1+ (1,0) [0|0] "" Vector__XXX
 SG_ CP_a031_apsVoltage m31 : 16|8@1+ (0.071568627,0) [0|0] "" Vector__XXX
 SG_ CP_a032_apsVoltage m32 : 16|8@1+ (0.071568627,0) [0|0] "" Vector__XXX
 SG_ CP_a035_latchState m35 : 16|2@1+ (1,0) [0|0] "" Vector__XXX
 SG_ CP_a036_latchCountsFiltered m36 : 16|16@1+ (0.00152590219,0) [0|0] "" Vector__XXX
 SG_ CP_a037_latchCountsFiltered m37 : 16|16@1+ (0.00152590219,0) [0|0] "" Vector__XXX
 SG_ CP_a038_latchCountsFiltered m38 : 16|16@1+ (0.00152590219,0) [0|0] "" Vector__XXX
 SG_ CP_a040_CP_doorCountsFiltered m40 : 16|16@1+ (0.00152590219,0) [0|0] "" Vector__XXX
 SG_ CP_a041_doorCounts m41 : 16|16@1+ (0.002,0) [0|0] "" Vector__XXX
 SG_ CP_a042_doorCounts m42 : 16|16@1+ (0.002,0) [0|0] "" Vector__XXX
 SG_ CP_a043_driftFlag m43 : 16|1@1+ (1,0) [0|0] "" Vector__XXX
 SG_ CP_a044_HVP_cpControl_MIA m44 : 16|1@1+ (1,0) [0|0] "" Vector__XXX
 SG_ CP_a045_VCSEC_authentication_MIA m45 : 16|1@1+ (1,0) [0|0] "" Vector__XXX
 SG_ CP_a046_FC_status_flag m46 : 16|1@1+ (1,0) [0|0] "" Vector__XXX
 SG_ CP_a047_okToUseHighPower_MIA m47 : 16|1@1+ (1,0) [0|0] "" Vector__XXX
 SG_ CP_a048_UI_chargeRequest_MIA m48 : 16|1@1+ (1,0) [0|0] "" Vector__XXX
 SG_ CP_a049_proximity m49 : 16|2@1+ (1,0) [0|0] "" Vector__XXX
 SG_ CP_a050_latch1NotConnected m50 : 16|1@1+ (1,0) [0|0] "" Vector__XXX
 SG_ CP_a051_doorCountsFiltered m51 : 16|12@1+ (0.025,0) [0|0] "" Vector__XXX
 SG_ CP_a054_latchCountsFiltered m54 : 16|16@1+ (0.00152590219,0) [0|0] "" Vector__XXX
 SG_ CP_a056_latchState m56 : 16|2@1+ (1,0) [0|0] "" Vector__XXX
 SG_ CP_a058_CP_pilot m58 : 16|3@1+ (1,0) [0|0] "" Vector__XXX
 SG_ CP_a060_PCS_chgStatus_MIA m60 : 16|1@1+ (1,0) [0|0] "" Vector__XXX
 SG_ CP_a061_controlState m61 : 16|4@1+ (1,0) [0|0] "" Vector__XXX
 SG_ CP_a062_FC_status m62 : 16|4@1+ (1,0) [0|0] "" Vector__XXX
 SG_ CP_a063_FC_status m63 : 16|4@1+ (1,0) [0|0] "" Vector__XXX
 SG_ CP_a065_doorIdFailed m65 : 16|1@1+ (1,0) [0|0] "" Vector__XXX
 SG_ CP_a066_pilotHigh m66 : 16|12@1- (0.008,0) [0|0] "" Vector__XXX
 SG_ CP_a067_cc1Voltage m67 : 16|14@1+ (0.001,0) [0|0] "" Vector__XXX
 SG_ CP_a068_doorCountsFiltered m68 : 16|12@1+ (0.025,0) [0|0] "" Vector__XXX
 SG_ CP_a069_inductiveSensor_raw m69 : 16|28@1+ (1,0) [0|0] "" Vector__XXX
 SG_ CP_a070_i2cIBCR m70 : 16|8@1+ (1,0) [0|0] "" Vector__XXX
 SG_ CP_a071_expectedMessage m71 : 16|5@1+ (1,0) [0|0] "" Vector__XXX
 SG_ CP_a072_currentMessage m72 : 16|5@1+ (1,0) [0|0] "" Vector__XXX
 SG_ CP_a073_ccsManagerState m73 : 16|3@1+ (1,0) [0|0] "" Vector__XXX
 SG_ CP_a074_slacState m74 : 16|4@1+ (1,0) [0|0] "" Vector__XXX
 SG_ CP_a075_evccState m75 : 16|3@1+ (1,0) [0|0] "" Vector__XXX
 SG_ CP_a076_inductiveSensor_raw m76 : 16|28@1+ (1,0) [0|0] "" Vector__XXX
 SG_ CP_a077_mac1Invalid m77 : 16|1@1+ (1,0) [0|0] "" Vector__XXX
 SG_ CP_a078_VC_tempAmbientFiltered m78 : 16|8@1+ (0.5,-40) [0|0] "" Vector__XXX
 SG_ CP_a079_VC_tempAmbientFiltered m79 : 16|8@1+ (0.5,-40) [0|0] "" Vector__XXX
 SG_ CP_a080_taskID m80 : 16|5@1+ (1,0) [0|0] "" Vector__XXX
 SG_ CP_a081_ivorNumber m81 : 16|3@1+ (1,0) [0|0] "" Vector__XXX
 SG_ CP_a083_taskID m83 : 16|5@1+ (1,0) [0|0] "" Vector__XXX
 SG_ CP_a084_proximityV m84 : 16|16@1+ (0.0001,0) [0|0] "" Vector__XXX
 SG_ CP_a085_absoluteTempFault m85 : 16|1@1+ (1,0) [0|0] "" Vector__XXX
 SG_ CP_a086_dcPinTemp m86 : 16|8@1+ (0.8039215686,-55) [0|0] "" Vector__XXX
 SG_ CP_a087_tempMeasuredTooHigh m87 : 16|1@1+ (1,0) [0|0] "" Vector__XXX
 SG_ CP_a088_tempMeasuredTooLow m88 : 16|1@1+ (1,0) [0|0] "" Vector__XXX
 SG_ CP_a089_gtwPlcSupportType m89 : 16|2@1+ (1,0) [0|0] "" Vector__XXX
 SG_ CP_a090_evseIsoStatus m90 : 16|3@1+ (1,0) [0|0] "" Vector__XXX
 SG_ CP_a091_fcType m91 : 16|3@1+ (1,0) [0|0] "" Vector__XXX
 SG_ CP_a093_appLoadingNumRetries m93 : 16|3@1+ (1,0) [0|0] "" Vector__XXX
 SG_ CP_a094_faultResetCount m94 : 16|8@1+ (1,0) [0|0] "" Vector__XXX
 SG_ CP_a095_packCurrent m95 : 16|13@1- (1,0) [0|0] "" Vector__XXX
 SG_ CP_a096_validPilotDetected m96 : 16|1@1+ (1,0) [0|0] "" Vector__XXX
 SG_ CP_a097_currentMode m97 : 16|4@1+ (1,0) [0|0] "" Vector__XXX
 SG_ CP_a098_CP_proximity m98 : 16|2@1+ (1,0) [0|0] "" Vector__XXX
 SG_ CP_a099_proximity m99 : 16|2@1+ (1,0) [0|0] "" Vector__XXX
 SG_ CP_a100_inletHarnessIdState m100 : 16|2@1+ (1,0) [0|0] "" Vector__XXX
 SG_ CP_a103_proximityV m103 : 16|16@1+ (0.0001,0) [0|0] "" Vector__XXX
 SG_ CP_a104_faultResetCount m104 : 16|8@1+ (1,0) [0|0] "" Vector__XXX
 SG_ CP_a105_i2c_scl_gpdi m105 : 16|1@1+ (1,0) [0|0] "" Vector__XXX
 SG_ CP_a106_controlState m106 : 16|4@1+ (1,0) [0|0] "" Vector__XXX
 SG_ CP_a109_thermistorId m109 : 16|3@1+ (1,0) [0|0] "" Vector__XXX
 SG_ CP_a110_thermistorId m110 : 16|3@1+ (1,0) [0|0] "" Vector__XXX
 SG_ CP_a111_heaterTemperature m111 : 16|8@1+ (0.8039215686,-55) [0|0] "" Vector__XXX
 SG_ CP_a112_heaterTemperature m112 : 16|8@1+ (0.8039215686,-55) [0|0] "" Vector__XXX
 SG_ CP_a113_heaterTemperature m113 : 16|8@1+ (0.8039215686,-55) [0|0] "" Vector__XXX
 SG_ CP_a114_v2gMessage m114 : 16|5@1+ (1,0) [0|0] "" Vector__XXX
 SG_ CP_a115_previousTransceiverState m115 : 16|3@1+ (1,0) [0|0] "" Vector__XXX
 SG_ CP_a116_hvCoverDetected m116 : 16|1@1+ (1,0) [0|0] "" Vector__XXX
 SG_ CP_a117_heaterTemperature m117 : 16|8@1+ (0.8039215686,-55) [0|0] "" Vector__XXX
 SG_ CP_a118_slacState m118 : 16|4@1+ (1,0) [0|0] "" Vector__XXX
 SG_ CP_a119_plcErr m119 : 16|3@1+ (1,0) [0|0] "" Vector__XXX
 SG_ CP_a120_oldProximtyV m120 : 16|10@1+ (0.004887585532746823,0) [0|0] "" Vector__XXX
 SG_ CP_a121_CP_status_MIA m121 : 16|1@1+ (1,0) [0|0] "" Vector__XXX
 SG_ CP_a122_plcModemErr m122 : 16|4@1+ (1,0) [0|0] "" Vector__XXX
 SG_ CP_a123_latchPotFiltered m123 : 16|16@1+ (0.00152590219,0) [0|0] "" Vector__XXX
 SG_ CP_a124_ivledState m124 : 16|2@1+ (1,0) [0|0] "" Vector__XXX
 SG_ CP_a125_okToUseHighPower m125 : 16|1@1+ (1,0) [0|0] "" Vector__XXX
 SG_ CP_a126_wakeOnUhfEnabled m126 : 16|1@1+ (1,0) [0|0] "" Vector__XXX
 SG_ CP_a127_HVLINK_cpControl_MIA m127 : 16|1@1+ (1,0) [0|0] "" Vector__XXX
 SG_ CP_a128_LVPowerState_MIA m128 : 16|1@1+ (1,0) [0|0] "" Vector__XXX
 SG_ CP_a129_bldcDriverState m129 : 16|2@1+ (1,0) [0|0] "" Vector__XXX
 SG_ CP_a130_retryCount m130 : 16|8@1+ (1,0) [0|0] "" Vector__XXX
 SG_ CP_a131_chargeProtocol m131 : 16|3@1+ (1,0) [0|0] "" Vector__XXX
 SG_ CP_a135_sdpErr m135 : 16|3@1+ (1,0) [0|0] "" Vector__XXX
 SG_ CP_a136_sdpType m136 : 16|3@1+ (1,0) [0|0] "" Vector__XXX
 SG_ CP_a137_plcForwardErr m137 : 16|4@1+ (1,0) [0|0] "" Vector__XXX
 SG_ CP_a138_FC_type m138 : 16|3@1+ (1,0) [0|0] "" Vector__XXX
 SG_ CP_a139_latchState m139 : 16|2@1+ (1,0) [0|0] "" Vector__XXX
 SG_ CP_a140_latchState m140 : 16|2@1+ (1,0) [0|0] "" Vector__XXX
 SG_ CP_a141_latchState m141 : 16|2@1+ (1,0) [0|0] "" Vector__XXX
 SG_ CP_a142_cc1Voltage m142 : 16|14@1+ (0.001,0) [0|0] "" Vector__XXX
 SG_ CP_a143_versionDetected m143 : 16|3@1+ (1,0) [0|0] "" Vector__XXX
 SG_ CP_a144_fileSystemError m144 : 16|1@1+ (1,0) [0|0] "" Vector__XXX
 SG_ CP_a146_v2gMessage m146 : 16|5@1+ (1,0) [0|0] "" Vector__XXX
 SG_ CP_a147_faultExitReason m147 : 16|3@1+ (1,0) [0|0] "" Vector__XXX
 SG_ CP_a148_doorControlState m148 : 16|3@1+ (1,0) [0|0] "" Vector__XXX
 SG_ CP_a149_period m149 : 16|9@1+ (1,0) [0|0] "" Vector__XXX
 SG_ CP_a150_rail m150 : 16|2@1+ (1,0) [0|0] "" Vector__XXX
 SG_ CP_a151_pilotHighMin m151 : 16|12@1+ (0.003540903540903541,0) [0|0] "" Vector__XXX
 SG_ CP_a152_swcanHighMismatchCount m152 : 16|5@1+ (1,0) [0|0] "" Vector__XXX
 SG_ CP_a153_acPinTempVelocity m153 : 16|10@1- (0.15748,0) [0|0] "" Vector__XXX
 SG_ CP_a154_acPinTempVelocity m154 : 16|10@1- (0.15748,0) [0|0] "" Vector__XXX
 SG_ CP_a155_hallSensorVoltage m155 : 16|10@1+ (0.004887585532746823,0) [0|0] "" Vector__XXX
 SG_ CP_a157_requestType m157 : 16|4@1+ (1,0) [0|0] "" Vector__XXX
 SG_ CP_a158_requestType m158 : 16|5@1+ (1,0) [0|0] "" Vector__XXX
 SG_ CP_a159_swcanHighMismatchCount m159 : 16|5@1+ (1,0) [0|0] "" Vector__XXX
 SG_ CP_a160_fcType m160 : 16|3@1+ (1,0) [0|0] "" Vector__XXX
 SG_ CP_a161_pilotHighMin m161 : 16|12@1+ (0.003540903540903541,0) [0|0] "" Vector__XXX
 SG_ CP_a162_swcanHighMismatchCount m162 : 16|5@1+ (1,0) [0|0] "" Vector__XXX
 SG_ CP_a163_cover1OpenCounts m163 : 16|12@1+ (0.025,0) [0|0] "" Vector__XXX
 SG_ CP_a164_VC_tempAmbientFiltered m164 : 16|8@1+ (0.5,-40) [0|0] "" Vector__XXX
 SG_ CP_a165_iecPilotState m165 : 16|4@1+ (1,0) [0|0] "" Vector__XXX
 SG_ CP_a166_hvFaultCanStatus m166 : 16|1@1+ (1,0) [0|0] "" Vector__XXX
 SG_ CP_a167_doorIdDetectionState m167 : 16|2@1+ (1,0) [0|0] "" Vector__XXX
 SG_ CP_a168_proxWiggleSource m168 : 16|3@1- (1,0) [0|0] "" Vector__XXX
 SG_ CP_a172_logId m172 : 16|4@1+ (1,0) [0|0] "" Vector__XXX
 SG_ CP_a173_cover1OpenCounts m173 : 16|12@1+ (0.025,0) [0|0] "" Vector__XXX
 SG_ CP_a174_impactedMsgFwdingChannel m174 : 16|2@1+ (1,0) [0|0] "" Vector__XXX
 SG_ CP_a175_impactedMsgFwdingChannel m175 : 16|2@1+ (1,0) [0|0] "" Vector__XXX
 SG_ CP_a176_EVSE_gridFormRequest_fla m176 : 16|1@1+ (1,0) [0|0] "" Vector__XXX
 SG_ CP_a177_evseVersion m177 : 16|5@1+ (1,0) [0|0] "" Vector__XXX
 SG_ CP_a178_slacRetriesFailed m178 : 16|1@1+ (1,0) [0|0] "" Vector__XXX
 SG_ CP_a179_errorType m179 : 16|4@1+ (1,0) [0|0] "" Vector__XXX
 SG_ CP_a182_errorType m182 : 16|4@1+ (1,0) [0|0] "" Vector__XXX
 SG_ CP_a183_errorType m183 : 16|2@1+ (1,0) [0|0] "" Vector__XXX
 SG_ CP_a184_requestType m184 : 16|3@1+ (1,0) [0|0] "" Vector__XXX
 SG_ CP_a185_authRejectedMessage m185 : 16|5@1+ (1,0) [0|0] "" Vector__XXX
 SG_ CP_a186_dmaErrorDetected m186 : 16|1@1+ (1,0) [0|0] "" Vector__XXX
 SG_ CP_a187_taskID m187 : 16|5@1+ (1,0) [0|0] "" Vector__XXX
 SG_ CP_a189_resistiveDividerVoltage m189 : 16|10@1+ (0.004887585532746823,0) [0|0] "" Vector__XXX
 SG_ CP_a201_uhfDoorRequestCounts m201 : 16|5@1+ (1,0) [0|0] "" Vector__XXX
 SG_ CP_a202_slacState m202 : 16|4@1+ (1,0) [0|0] "" Vector__XXX
 SG_ CP_a203_chargeProtocol m203 : 16|3@1+ (1,0) [0|0] "" Vector__XXX
 SG_ CP_a204_sdpErr m204 : 16|3@1+ (1,0) [0|0] "" Vector__XXX
 SG_ CP_a205_doorPotFiltered m205 : 16|12@1+ (0.025,0) [0|0] "" Vector__XXX
 SG_ CP_a206_peToChassisVoltage m206 : 16|12@1- (0.003224230581338544,0) [0|0] "" Vector__XXX
 SG_ CP_alertType : 15|1@1+ (1,0) [0|0] "" Vector__XXX
 SG_ CP_alertID M : 0|15@1+ (1,0) [0|0] "" Vector__XXX

BO_ 1296 HVP_bootID: 12 Vector__XXX
 SG_ HVP_bootFirmwareType : 63|8@0+ (1,0) [0|0] "" Vector__XXX
 SG_ HVP_bootUsageId : 39|16@0+ (1,0) [0|0] "" Vector__XXX
 SG_ HVP_bootAssemblyId : 31|8@0+ (1,0) [0|0] "" Vector__XXX
 SG_ HVP_bootPcbaId : 23|8@0+ (1,0) [0|0] "" Vector__XXX
 SG_ HVP_bootComponentId : 7|16@0+ (1,0) [0|0] "" Vector__XXX

CM_ BO_ 1274 "ESP32-DualCAN Model3_CH. Not seen on this car in the logs.";
CM_ BO_ 1278 "ESP32-DualCAN Model3_CH. Not seen on this car in the logs.";
CM_ BO_ 1279 "ESP32-DualCAN Model3_VEH. Seen on this car: 8-byte frames; fit weak (bits covered 0%, mux 100%, ranges 100%).";
CM_ BO_ 1281 "ESP32-DualCAN Model3_VEH. Not seen on this car in the logs.";
CM_ BO_ 1283 "ESP32-DualCAN Model3_VEH. Not seen on this car in the logs.";
CM_ BO_ 1284 "ESP32-DualCAN Model3_VEH. Not seen on this car in the logs.";
CM_ BO_ 1285 "ESP32-DualCAN Model3_CH. Seen on this car: 8-byte frames; fit good (bits covered 100%, mux 100%, ranges 100%).";
VAL_ 1285 ESP_alertState 0 "CLEARED" 1 "SET" ;
VAL_ 1285 ESP_alertID 0 "ALERT_DO_NOT_USE_ZERO" 1 "a001_DriverDoorOpen" 2 "a002_DoorOpen" 3 "a003_TrunkOpen" 4 "a004_FrunkOpen" 5 "a005_HeadlightsOnDoorOpen" 6 "a006_RemoteServiceAlert" 7 "a007_SoftPackConfigMismatch" 8 "a008_TouchScreenError" 9 "a009_SquashfsError" 10 "a010_MapsMissing" 11 "a011_IncorrectMap" 12 "a012_NotOnPrivateProperty" 13 "a013_TPMSHardWarning" 14 "a014_TPMSSoftWarning" 15 "a015_TPMSOverPressureWarning" 16 "a016_TPMSTemperatureWarning" 17 "a017_TPMSSystemFault" 18 "a018_SlipStartOn" 19 "a019_ParkBrakeFault" 20 "a020_SteeringReduced" 21 "a021_RearSeatbeltUnbuckled" 22 "a022_ApeFusesEtc" 23 "a023_CellInternetCheckFailed" 24 "a024_WifiInternetCheckFailed" 25 "a025_WifiOnlineCheckFailed" 26 "a026_ModemResetLoopDetected" 27 "a027_AutoSteerMIA" 28 "a028_FrontTrunkPopupClosed" 29 "a029_ModemMIA" 30 "a030_ModemVMCrash" 31 "a031_BrakeFluidLow" 32 "a032_CellModemRecoveryResets" 33 "a033_ApTrialExpired" 34 "a034_WakeupProblem" 35 "a035_AudioWatchdogKernelError" 36 "a036_AudioWatchdogHfpError" 37 "a037_AudioWatchdogXrunStormError" 38 "a038_AudioWatchdogA2bI2cLockupError" 39 "a039_AudioA2bNeedRediscovery" 40 "a040_HomelinkTransmit" 41 "a041_AudioDmesgXrun" 42 "a042_AudioDmesgRtThrottling" 43 "a043_InvalidMapDataOverride" 44 "a044_AudioDmesgDspException" 45 "a045_ECallNeedsService" 46 "a046_BackupCameraStreamError" 47 "a047_CellRoamingDisallowed" 48 "a048_AudioPremiumAmpCheckFailed" 49 "a049_BrakeShiftRequired" 50 "a050_BackupCameraIPUTimeout" 51 "a051_BackupCameraFrameTimeout" 52 "a052_KernelPanicReported" 53 "a053_QtCarExitError" 54 "a054_AudioBoostPowerBad" 55 "a055_ManualECallDisabled" 56 "a056_ManualECallButtonDisconnected" 57 "a057_CellAntennaDisconnected" 58 "a058_GPSAntennaDisconnected" 59 "a059_ECallSpeakerDisconnected" 60 "a060_ECallMicDisconnected" 61 "a061_SIMTestFailed" 62 "a062_ENSTestFailed" 63 "a063_CellularTestFailed" 64 "a064_ModemFirmwareTestFailed" 65 "a065_WiFiRecoveryReset" 66 "a066_GpuHangDetected" 67 "a067_WarnOnI915" 68 "a068_VideoUnexpectedExit" 69 "a069_VideoUDPTimeout" 70 "a070_VideoPipelineWarning" 71 "a071_VideoPipelineError" 72 "a072_ECallAnalogMicFailed" 73 "a073_ECallDigitalMicFailed" 74 "a074_EMMCHangDetected" 75 "a075_BackupCameraInitError" 76 "a076_NumFalseManualECalls" 77 "a077_AudioA2bMicChannelSwap" 78 "a078_DashcamUsbDriveUnmountable" 79 "a079_DashcamUsbDriveFull" 80 "a080_DashcamUsbDriveSlow" 81 "a081_CellModemSearchExpired" 82 "a082_NumModemRebootStuckInECall" 83 "a083_ECallProxyWatchdogTriggered" 84 "a084_SerializerError" 85 "a085_DeserializerError" 86 "a086_TouchEnumerationError" 87 "a087_BmpReset" 88 "a088_CellRemovableSimMissing" 89 "a089_RadioSoftResetError" 90 "a090_RadioPingFailError" 91 "a091_VehicleLinkStall" 92 "a092_updateStarted" 93 "a093_updateEnded" 94 "a094_ModemPowerOnFailure" 95 "a095_CidStorageRunningLow" 96 "a096_VideodPipelineIssueDetected" 97 "a097_AudiodRestarted" 98 "a098_DiskCheckFailure" 99 "a099_eMMCStatusError" 100 "a100_eMMCFTLError" 101 "a101_wifiStackProblem" 102 "a102_A2bDiscoveryFailed" 103 "a103_UsbHubNotEnumerating" 104 "a104_DashcamUsbDriveMissing" 105 "a105_firmwareReinstallRequested" 106 "a106_rebootBackstopTriggered" 107 "a107_DashcamUsbDriveTooBigForVfatFsck" 108 "a108_DashcamUsbDriveGettingFull" 109 "a109_DashcamUsbDriveTooSmall" 110 "a110_DashcamUsbDriveCorrupt" 111 "a111_DashcamUsbDriveWrongPort" 112 "a112_badUSBDevice" 113 "a113_DashcamHasOnboardSentryClips" ;
CM_ BO_ 1289 "ESP32-DualCAN Model3_VEH. Seen on this car: 5-byte frames; fit poor (bits covered 0%, mux 100%, ranges 100%).";
CM_ BO_ 1290 "ESP32-DualCAN Model3_VEH. Not seen on this car in the logs.";
VAL_ 1290 HVP_a025_packVoltage 65535 "SNA" ;
VAL_ 1290 HVP_a026_hvilStatus 0 "DISABLED" 1 "OPEN" 2 "CLOSED" 3 "SNA" ;
VAL_ 1290 HVP_a028_packVoltage 65535 "SNA" ;
VAL_ 1290 HVP_a053_packVoltage 65535 "SNA" ;
VAL_ 1290 HVP_alertID 0 "ALERT_DO_NOT_USE_ZERO" 1 "a001_DriverDoorOpen" 2 "a002_DoorOpen" 3 "a003_TrunkOpen" 4 "a004_FrunkOpen" 5 "a005_HeadlightsOnDoorOpen" 6 "a006_RemoteServiceAlert" 7 "a007_SoftPackConfigMismatch" 8 "a008_TouchScreenError" 9 "a009_SquashfsError" 10 "a010_MapsMissing" 11 "a011_IncorrectMap" 12 "a012_NotOnPrivateProperty" 13 "a013_TPMSHardWarning" 14 "a014_TPMSSoftWarning" 15 "a015_TPMSOverPressureWarning" 16 "a016_TPMSTemperatureWarning" 17 "a017_TPMSSystemFault" 18 "a018_SlipStartOn" 19 "a019_ParkBrakeFault" 20 "a020_SteeringReduced" 21 "a021_RearSeatbeltUnbuckled" 22 "a022_ApeFusesEtc" 23 "a023_CellInternetCheckFailed" 24 "a024_WifiInternetCheckFailed" 25 "a025_WifiOnlineCheckFailed" 26 "a026_ModemResetLoopDetected" 27 "a027_AutoSteerMIA" 28 "a028_FrontTrunkPopupClosed" 29 "a029_ModemMIA" 30 "a030_ModemVMCrash" 31 "a031_BrakeFluidLow" 32 "a032_CellModemRecoveryResets" 33 "a033_ApTrialExpired" 34 "a034_WakeupProblem" 35 "a035_AudioWatchdogKernelError" 36 "a036_AudioWatchdogHfpError" 37 "a037_AudioWatchdogXrunStormError" 38 "a038_AudioWatchdogA2bI2cLockupError" 39 "a039_AudioA2bNeedRediscovery" 40 "a040_HomelinkTransmit" 41 "a041_AudioDmesgXrun" 42 "a042_AudioDmesgRtThrottling" 43 "a043_InvalidMapDataOverride" 44 "a044_AudioDmesgDspException" 45 "a045_ECallNeedsService" 46 "a046_BackupCameraStreamError" 47 "a047_CellRoamingDisallowed" 48 "a048_AudioPremiumAmpCheckFailed" 49 "a049_BrakeShiftRequired" 50 "a050_BackupCameraIPUTimeout" 51 "a051_BackupCameraFrameTimeout" 52 "a052_KernelPanicReported" 53 "a053_QtCarExitError" 54 "a054_AudioBoostPowerBad" 55 "a055_ManualECallDisabled" 56 "a056_ManualECallButtonDisconnected" 57 "a057_CellAntennaDisconnected" 58 "a058_GPSAntennaDisconnected" 59 "a059_ECallSpeakerDisconnected" 60 "a060_ECallMicDisconnected" 61 "a061_SIMTestFailed" 62 "a062_ENSTestFailed" 63 "a063_CellularTestFailed" 64 "a064_ModemFirmwareTestFailed" 65 "a065_WiFiRecoveryReset" 66 "a066_GpuHangDetected" 67 "a067_WarnOnI915" 68 "a068_VideoUnexpectedExit" 69 "a069_VideoUDPTimeout" 70 "a070_VideoPipelineWarning" 71 "a071_VideoPipelineError" 72 "a072_ECallAnalogMicFailed" 73 "a073_ECallDigitalMicFailed" 74 "a074_EMMCHangDetected" 75 "a075_BackupCameraInitError" 76 "a076_NumFalseManualECalls" 77 "a077_AudioA2bMicChannelSwap" 78 "a078_DashcamUsbDriveUnmountable" 79 "a079_DashcamUsbDriveFull" 80 "a080_DashcamUsbDriveSlow" 81 "a081_CellModemSearchExpired" 82 "a082_NumModemRebootStuckInECall" 83 "a083_ECallProxyWatchdogTriggered" 84 "a084_SerializerError" 85 "a085_DeserializerError" 86 "a086_TouchEnumerationError" 87 "a087_BmpReset" 88 "a088_CellRemovableSimMissing" 89 "a089_RadioSoftResetError" 90 "a090_RadioPingFailError" 91 "a091_VehicleLinkStall" 92 "a092_updateStarted" 93 "a093_updateEnded" 94 "a094_ModemPowerOnFailure" 95 "a095_CidStorageRunningLow" 96 "a096_VideodPipelineIssueDetected" 97 "a097_AudiodRestarted" 98 "a098_DiskCheckFailure" 99 "a099_eMMCStatusError" 100 "a100_eMMCFTLError" 101 "a101_wifiStackProblem" 102 "a102_A2bDiscoveryFailed" 103 "a103_UsbHubNotEnumerating" 104 "a104_DashcamUsbDriveMissing" 105 "a105_firmwareReinstallRequested" 106 "a106_rebootBackstopTriggered" 107 "a107_DashcamUsbDriveTooBigForVfatFsck" 108 "a108_DashcamUsbDriveGettingFull" 109 "a109_DashcamUsbDriveTooSmall" 110 "a110_DashcamUsbDriveCorrupt" 111 "a111_DashcamUsbDriveWrongPort" 112 "a112_badUSBDevice" 113 "a113_DashcamHasOnboardSentryClips" ;
CM_ BO_ 1294 "ESP32-DualCAN Model3_VEH. Not seen on this car in the logs.";
VAL_ 1294 CP_a120_cableType 0 "IEC" 1 "SAE" 2 "GB_AC" 3 "GB_DC" 4 "SNA" ;
VAL_ 1294 CP_a065_pilotState 0 "READY" 1 "IDLE" 2 "FAULTED" 3 "SNA" ;
VAL_ 1294 CP_a054_CP_proximity 0 "SNA" 1 "DISCONNECTED" 2 "UNLATCHED" 3 "LATCHED" ;
VAL_ 1294 CP_a095_ambientTemp 4294966273 "SNA" ;
VAL_ 1294 CP_a153_ambientTemp 4294966273 "SNA" ;
VAL_ 1294 CP_a154_ambientTemp 4294966273 "SNA" ;
VAL_ 1294 CP_a005_packCurrent 4294934528 "SNA" ;
VAL_ 1294 CP_a066_proximity 0 "SNA" 1 "DISCONNECTED" 2 "UNLATCHED" 3 "LATCHED" ;
VAL_ 1294 CP_a036_latchState 0 "SNA" 1 "DISENGAGED" 2 "ENGAGED" 3 "BLOCKING" ;
VAL_ 1294 CP_a037_latchState 0 "SNA" 1 "DISENGAGED" 2 "ENGAGED" 3 "BLOCKING" ;
VAL_ 1294 CP_a038_latchState 0 "SNA" 1 "DISENGAGED" 2 "ENGAGED" 3 "BLOCKING" ;
VAL_ 1294 CP_a054_latchState 0 "SNA" 1 "DISENGAGED" 2 "ENGAGED" 3 "BLOCKING" ;
VAL_ 1294 CP_a123_latchState 0 "SNA" 1 "DISENGAGED" 2 "ENGAGED" 3 "BLOCKING" ;
VAL_ 1294 CP_a137_state 0 "STANDBY" 1 "DRIVE" 2 "SUPPORT" 3 "CHARGE" 4 "FEIM" 5 "CLEAR_FAULT" 6 "FAULT" 7 "WELD" 8 "TEST" 9 "SNA" 10 "DIAG" ;
VAL_ 1294 CP_a058_CP_proximity 0 "SNA" 1 "DISCONNECTED" 2 "UNLATCHED" 3 "LATCHED" ;
VAL_ 1294 CP_a058_latchState 0 "SNA" 1 "DISENGAGED" 2 "ENGAGED" 3 "BLOCKING" ;
VAL_ 1294 CP_a149_iecPilotState 0 "B1" 1 "B2" 2 "B3" 3 "C1" 4 "C2" 5 "C3" 6 "E" 7 "F" 8 "NUM" 9 "SNA" ;
VAL_ 1294 CP_a149_pilotState 0 "READY" 1 "IDLE" 2 "FAULTED" 3 "SNA" ;
VAL_ 1294 CP_a056_packCurrent 4294934528 "SNA" ;
VAL_ 1294 CP_a058_FC_status 0 "DISABLED" 1 "ENABLED" 2 "TEMPORARY_FAILURE" 3 "SNA" ;
VAL_ 1294 CP_a111_VC_tempAmbientFiltered 0 "SNA" ;
VAL_ 1294 CP_a136_pilotState 0 "READY" 1 "IDLE" 2 "FAULTED" 3 "SNA" ;
VAL_ 1294 CP_a138_CP_proximity 0 "SNA" 1 "DISCONNECTED" 2 "UNLATCHED" 3 "LATCHED" ;
VAL_ 1294 CP_a056_CP_proximity 0 "SNA" 1 "DISCONNECTED" 2 "UNLATCHED" 3 "LATCHED" ;
VAL_ 1294 CP_a062_FC_type 0 "US_TESLA" 1 "EURO_IEC" 2 "GB" 3 "IEC_CCS" ;
VAL_ 1294 CP_a063_FC_type 0 "US_TESLA" 1 "EURO_IEC" 2 "GB" 3 "IEC_CCS" ;
VAL_ 1294 CP_a029_CP_proximity 0 "SNA" 1 "DISCONNECTED" 2 "UNLATCHED" 3 "LATCHED" ;
VAL_ 1294 CP_a058_CC_pilot 0 "NONE" 1 "FAULTED" 2 "LINE_CHARGE" 3 "FAST_CHARGE" 4 "IDLE" 5 "INVALID" 6 "UNUSED_6" 7 "SNA" ;
VAL_ 1294 CP_a135_pilotState 0 "READY" 1 "IDLE" 2 "FAULTED" 3 "SNA" ;
VAL_ 1294 CP_a138_latchState 0 "SNA" 1 "DISENGAGED" 2 "ENGAGED" 3 "BLOCKING" ;
VAL_ 1294 CP_a204_pilotState 0 "READY" 1 "IDLE" 2 "FAULTED" 3 "SNA" ;
VAL_ 1294 CP_a099_pilot 0 "NONE" 1 "FAULTED" 2 "LINE_CHARGE" 3 "FAST_CHARGE" 4 "IDLE" 5 "INVALID" 6 "UNUSED_6" 7 "SNA" ;
VAL_ 1294 CP_a139_CP_proximity 0 "SNA" 1 "DISCONNECTED" 2 "UNLATCHED" 3 "LATCHED" ;
VAL_ 1294 CP_a140_CP_proximity 0 "SNA" 1 "DISCONNECTED" 2 "UNLATCHED" 3 "LATCHED" ;
VAL_ 1294 CP_a141_CP_proximity 0 "SNA" 1 "DISCONNECTED" 2 "UNLATCHED" 3 "LATCHED" ;
VAL_ 1294 CP_a150_state 0 "STANDBY" 1 "DRIVE" 2 "SUPPORT" 3 "CHARGE" 4 "FEIM" 5 "CLEAR_FAULT" 6 "FAULT" 7 "WELD" 8 "TEST" 9 "SNA" 10 "DIAG" ;
VAL_ 1294 CP_a029_CP_pilot 0 "NONE" 1 "FAULTED" 2 "LINE_CHARGE" 3 "FAST_CHARGE" 4 "IDLE" 5 "INVALID" 6 "UNUSED_6" 7 "SNA" ;
VAL_ 1294 CP_a035_latchState 0 "SNA" 1 "DISENGAGED" 2 "ENGAGED" 3 "BLOCKING" ;
VAL_ 1294 CP_a049_proximity 0 "SNA" 1 "DISCONNECTED" 2 "UNLATCHED" 3 "LATCHED" ;
VAL_ 1294 CP_a056_latchState 0 "SNA" 1 "DISENGAGED" 2 "ENGAGED" 3 "BLOCKING" ;
VAL_ 1294 CP_a058_CP_pilot 0 "NONE" 1 "FAULTED" 2 "LINE_CHARGE" 3 "FAST_CHARGE" 4 "IDLE" 5 "INVALID" 6 "UNUSED_6" 7 "SNA" ;
VAL_ 1294 CP_a061_controlState 0 "INIT" 1 "CONFIG" 2 "IDLE" 3 "CALIBRATE" 4 "PREPARE_RX" 5 "RX" 6 "CHECK_RX" 7 "READ_RXFIFO" 8 "HANDLE_FOUND" 9 "SLEEP" 10 "FAULT" ;
VAL_ 1294 CP_a062_FC_status 0 "DISABLED" 1 "ENABLED" 2 "TEMPORARY_FAILURE" 3 "SNA" ;
VAL_ 1294 CP_a063_FC_status 0 "DISABLED" 1 "ENABLED" 2 "TEMPORARY_FAILURE" 3 "SNA" ;
VAL_ 1294 CP_a078_VC_tempAmbientFiltered 0 "SNA" ;
VAL_ 1294 CP_a079_VC_tempAmbientFiltered 0 "SNA" ;
VAL_ 1294 CP_a095_packCurrent 4294934528 "SNA" ;
VAL_ 1294 CP_a098_CP_proximity 0 "SNA" 1 "DISCONNECTED" 2 "UNLATCHED" 3 "LATCHED" ;
VAL_ 1294 CP_a099_proximity 0 "SNA" 1 "DISCONNECTED" 2 "UNLATCHED" 3 "LATCHED" ;
VAL_ 1294 CP_a106_controlState 0 "INIT" 1 "CONFIG" 2 "IDLE" 3 "CALIBRATE" 4 "PREPARE_RX" 5 "RX" 6 "CHECK_RX" 7 "READ_RXFIFO" 8 "HANDLE_FOUND" 9 "SLEEP" 10 "FAULT" ;
VAL_ 1294 CP_a138_FC_type 0 "US_TESLA" 1 "EURO_IEC" 2 "GB" 3 "IEC_CCS" ;
VAL_ 1294 CP_a139_latchState 0 "SNA" 1 "DISENGAGED" 2 "ENGAGED" 3 "BLOCKING" ;
VAL_ 1294 CP_a140_latchState 0 "SNA" 1 "DISENGAGED" 2 "ENGAGED" 3 "BLOCKING" ;
VAL_ 1294 CP_a141_latchState 0 "SNA" 1 "DISENGAGED" 2 "ENGAGED" 3 "BLOCKING" ;
VAL_ 1294 CP_a148_doorControlState 0 "doorInit" 1 "doorIdle" 2 "doorOpenRequested" 3 "doorOpening" 4 "doorSenseOpen" 5 "doorClosing" 6 "doorSenseClosed" ;
VAL_ 1294 CP_a164_VC_tempAmbientFiltered 0 "SNA" ;
VAL_ 1294 CP_a165_iecPilotState 0 "B1" 1 "B2" 2 "B3" 3 "C1" 4 "C2" 5 "C3" 6 "E" 7 "F" 8 "NUM" 9 "SNA" ;
VAL_ 1294 CP_alertID 0 "ALERT_DO_NOT_USE_ZERO" 1 "a001_DriverDoorOpen" 2 "a002_DoorOpen" 3 "a003_TrunkOpen" 4 "a004_FrunkOpen" 5 "a005_HeadlightsOnDoorOpen" 6 "a006_RemoteServiceAlert" 7 "a007_SoftPackConfigMismatch" 8 "a008_TouchScreenError" 9 "a009_SquashfsError" 10 "a010_MapsMissing" 11 "a011_IncorrectMap" 12 "a012_NotOnPrivateProperty" 13 "a013_TPMSHardWarning" 14 "a014_TPMSSoftWarning" 15 "a015_TPMSOverPressureWarning" 16 "a016_TPMSTemperatureWarning" 17 "a017_TPMSSystemFault" 18 "a018_SlipStartOn" 19 "a019_ParkBrakeFault" 20 "a020_SteeringReduced" 21 "a021_RearSeatbeltUnbuckled" 22 "a022_ApeFusesEtc" 23 "a023_CellInternetCheckFailed" 24 "a024_WifiInternetCheckFailed" 25 "a025_WifiOnlineCheckFailed" 26 "a026_ModemResetLoopDetected" 27 "a027_AutoSteerMIA" 28 "a028_FrontTrunkPopupClosed" 29 "a029_ModemMIA" 30 "a030_ModemVMCrash" 31 "a031_BrakeFluidLow" 32 "a032_CellModemRecoveryResets" 33 "a033_ApTrialExpired" 34 "a034_WakeupProblem" 35 "a035_AudioWatchdogKernelError" 36 "a036_AudioWatchdogHfpError" 37 "a037_AudioWatchdogXrunStormError" 38 "a038_AudioWatchdogA2bI2cLockupError" 39 "a039_AudioA2bNeedRediscovery" 40 "a040_HomelinkTransmit" 41 "a041_AudioDmesgXrun" 42 "a042_AudioDmesgRtThrottling" 43 "a043_InvalidMapDataOverride" 44 "a044_AudioDmesgDspException" 45 "a045_ECallNeedsService" 46 "a046_BackupCameraStreamError" 47 "a047_CellRoamingDisallowed" 48 "a048_AudioPremiumAmpCheckFailed" 49 "a049_BrakeShiftRequired" 50 "a050_BackupCameraIPUTimeout" 51 "a051_BackupCameraFrameTimeout" 52 "a052_KernelPanicReported" 53 "a053_QtCarExitError" 54 "a054_AudioBoostPowerBad" 55 "a055_ManualECallDisabled" 56 "a056_ManualECallButtonDisconnected" 57 "a057_CellAntennaDisconnected" 58 "a058_GPSAntennaDisconnected" 59 "a059_ECallSpeakerDisconnected" 60 "a060_ECallMicDisconnected" 61 "a061_SIMTestFailed" 62 "a062_ENSTestFailed" 63 "a063_CellularTestFailed" 64 "a064_ModemFirmwareTestFailed" 65 "a065_WiFiRecoveryReset" 66 "a066_GpuHangDetected" 67 "a067_WarnOnI915" 68 "a068_VideoUnexpectedExit" 69 "a069_VideoUDPTimeout" 70 "a070_VideoPipelineWarning" 71 "a071_VideoPipelineError" 72 "a072_ECallAnalogMicFailed" 73 "a073_ECallDigitalMicFailed" 74 "a074_EMMCHangDetected" 75 "a075_BackupCameraInitError" 76 "a076_NumFalseManualECalls" 77 "a077_AudioA2bMicChannelSwap" 78 "a078_DashcamUsbDriveUnmountable" 79 "a079_DashcamUsbDriveFull" 80 "a080_DashcamUsbDriveSlow" 81 "a081_CellModemSearchExpired" 82 "a082_NumModemRebootStuckInECall" 83 "a083_ECallProxyWatchdogTriggered" 84 "a084_SerializerError" 85 "a085_DeserializerError" 86 "a086_TouchEnumerationError" 87 "a087_BmpReset" 88 "a088_CellRemovableSimMissing" 89 "a089_RadioSoftResetError" 90 "a090_RadioPingFailError" 91 "a091_VehicleLinkStall" 92 "a092_updateStarted" 93 "a093_updateEnded" 94 "a094_ModemPowerOnFailure" 95 "a095_CidStorageRunningLow" 96 "a096_VideodPipelineIssueDetected" 97 "a097_AudiodRestarted" 98 "a098_DiskCheckFailure" 99 "a099_eMMCStatusError" 100 "a100_eMMCFTLError" 101 "a101_wifiStackProblem" 102 "a102_A2bDiscoveryFailed" 103 "a103_UsbHubNotEnumerating" 104 "a104_DashcamUsbDriveMissing" 105 "a105_firmwareReinstallRequested" 106 "a106_rebootBackstopTriggered" 107 "a107_DashcamUsbDriveTooBigForVfatFsck" 108 "a108_DashcamUsbDriveGettingFull" 109 "a109_DashcamUsbDriveTooSmall" 110 "a110_DashcamUsbDriveCorrupt" 111 "a111_DashcamUsbDriveWrongPort" 112 "a112_badUSBDevice" 113 "a113_DashcamHasOnboardSentryClips" ;
CM_ BO_ 1296 "ESP32-DualCAN Model3_VEH. Not seen on this car in the logs.";
